VERSION ""

NS_ :

BS_:

BU_: CAN2 CAN1
VAL_TABLE_ VCU_DASH_GearRange_t 3 "Gear_Invalid" 2 "Gear_Reverse" 1 "Gear_Drive" 0 "Gear_Neutral" ;

BO_ 3221225472 VECTOR__INDEPENDENT_SIG_MSG: 0 Vector__XXX
 SG_ VCU_DVD_SOCLowerFailure : 0|1@0+ (1,0) [0|0] "" Vector__XXX
 SG_ VCU_DASH_VehicleController : 0|2@1+ (1,0) [0|0] "" Vector__XXX
 SG_ New_Signal_230 : 0|8@1+ (1,0) [0|0] "" Vector__XXX
 SG_ New_Signal_228 : 0|8@1+ (1,0) [0|0] "" Vector__XXX
 SG_ New_Signal_227 : 0|8@1+ (1,0) [0|0] "" Vector__XXX
 SG_ New_Signal_226 : 0|8@1+ (1,0) [0|0] "" Vector__XXX
 SG_ New_Signal_224 : 0|8@1+ (1,0) [0|0] "" Vector__XXX
 SG_ New_Signal_223 : 0|8@1+ (1,0) [0|0] "" Vector__XXX
 SG_ New_Signal_222 : 0|8@1+ (1,0) [0|0] "" Vector__XXX
 SG_ New_Signal_164 : 0|8@1+ (1,0) [0|0] "" Vector__XXX
 SG_ New_Signal_163 : 0|8@1+ (1,0) [0|0] "" Vector__XXX
 SG_ New_Signal_148 : 0|8@1+ (1,0) [0|0] "" Vector__XXX
 SG_ New_Signal_147 : 0|8@1+ (1,0) [0|0] "" Vector__XXX
 SG_ New_Signal_146 : 0|8@1+ (1,0) [0|0] "" Vector__XXX
 SG_ New_Signal_145 : 0|8@1+ (1,0) [0|0] "" Vector__XXX
 SG_ New_Signal_104 : 0|8@1+ (1,0) [0|0] "" Vector__XXX
 SG_ New_Signal_103 : 0|8@1+ (1,0) [0|0] "" Vector__XXX
 SG_ New_Signal_102 : 0|8@1+ (1,0) [0|0] "" Vector__XXX
 SG_ ERROR_CODE : 0|2@1- (1,0) [0|0] "" Vector__XXX
 SG_ DIN_P53 : 0|8@1+ (1,0) [0|255] "" Vector__XXX
 SG_ VCU_Vechicle_Speed : 0|8@1+ (1,0) [0|0] "km/h" Vector__XXX
 SG_ VCU_Motor_Rpm : 0|16@0+ (1,0) [0|30000] "rpm" Vector__XXX
 SG_ VCU_Driving_Range : 0|16@1+ (1,0) [0|0] "km" Vector__XXX
 SG_ New_Signal_211 : 0|8@1+ (1,0) [0|0] "" Vector__XXX
 SG_ New_Signal_213 : 0|8@1+ (1,0) [0|0] "" Vector__XXX
 SG_ New_Signal_212 : 0|8@1+ (1,0) [0|0] "" Vector__XXX
 SG_ New_Signal_211 : 0|8@1+ (1,0) [0|0] "" Vector__XXX
 SG_ New_Signal_210 : 0|8@1+ (1,0) [0|0] "" Vector__XXX
 SG_ New_Signal_196 : 0|8@1+ (1,0) [0|0] "" Vector__XXX
 SG_ New_Signal_195 : 0|8@1+ (1,0) [0|0] "" Vector__XXX
 SG_ New_Signal_194 : 0|8@1+ (1,0) [0|0] "" Vector__XXX
 SG_ New_Signal_193 : 0|8@1+ (1,0) [0|0] "" Vector__XXX
 SG_ New_Signal_192 : 0|8@1+ (1,0) [0|0] "" Vector__XXX
 SG_ New_Signal_191 : 0|8@1+ (1,0) [0|0] "" Vector__XXX
 SG_ New_Signal_170 : 0|8@1+ (1,0) [0|0] "" Vector__XXX
 SG_ New_Signal_169 : 0|8@1+ (1,0) [0|0] "" Vector__XXX
 SG_ New_Signal_168 : 0|8@1+ (1,0) [0|0] "" Vector__XXX
 SG_ New_Signal_167 : 0|8@1+ (1,0) [0|0] "" Vector__XXX
 SG_ New_Signal_166 : 0|8@1+ (1,0) [0|0] "" Vector__XXX
 SG_ New_Signal_165 : 0|8@1+ (1,0) [0|0] "" Vector__XXX

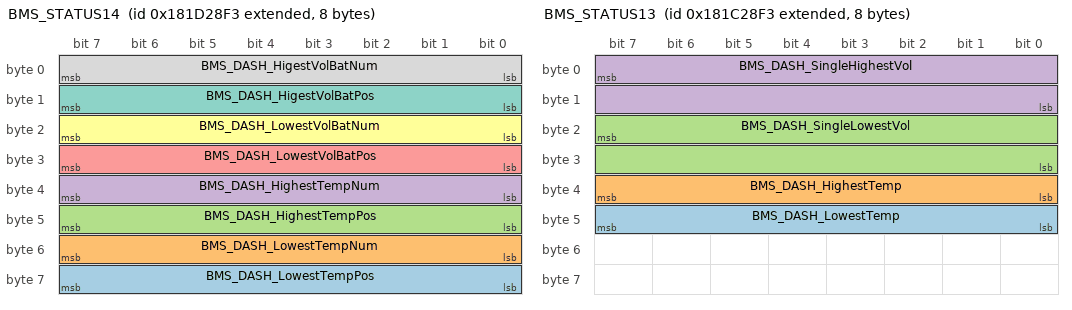
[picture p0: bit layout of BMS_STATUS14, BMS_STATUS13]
BO_ 2552047859 BMS_STATUS14: 8 CAN1
 SG_ BMS_DASH_LowestTempPos : 63|8@0+ (1,0) [0|0] "" Vector__XXX
 SG_ BMS_DASH_LowestTempNum : 55|8@0+ (1,0) [0|0] "" Vector__XXX
 SG_ BMS_DASH_HighestTempPos : 47|8@0+ (1,0) [0|0] "" Vector__XXX
 SG_ BMS_DASH_HighestTempNum : 39|8@0+ (1,0) [0|0] "" Vector__XXX
 SG_ BMS_DASH_LowestVolBatPos : 31|8@0+ (1,0) [0|0] "" Vector__XXX
 SG_ BMS_DASH_LowestVolBatNum : 23|8@0+ (1,0) [0|0] "" Vector__XXX
 SG_ BMS_DASH_HigestVolBatPos : 15|8@0+ (1,0) [0|0] "" Vector__XXX
 SG_ BMS_DASH_HigestVolBatNum : 7|8@0+ (1,0) [0|0] "" Vector__XXX

BO_ 2551982323 BMS_STATUS13: 8 CAN1
 SG_ BMS_DASH_LowestTemp : 47|8@0+ (1,-40) [-40|210] "" Vector__XXX
 SG_ BMS_DASH_HighestTemp : 39|8@0+ (1,-40) [-40|210] "" Vector__XXX
 SG_ BMS_DASH_SingleLowestVol : 23|16@0+ (0.01,0) [0|10] "V" Vector__XXX
 SG_ BMS_DASH_SingleHighestVol : 7|16@0+ (0.01,0) [0|10] "V" Vector__XXX

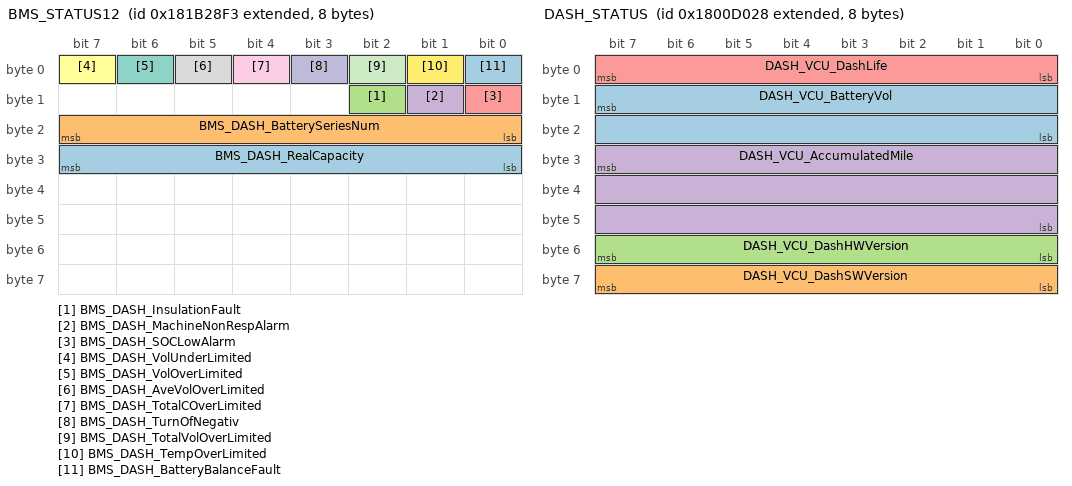
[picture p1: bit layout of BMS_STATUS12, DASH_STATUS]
BO_ 2551916787 BMS_STATUS12: 8 CAN1
 SG_ BMS_DASH_RealCapacity : 31|8@0+ (1,0) [0|510] "Ah" Vector__XXX
 SG_ BMS_DASH_BatterySeriesNum : 23|8@0+ (1,0) [0|0] "" Vector__XXX
 SG_ BMS_DASH_InsulationFault : 10|1@0+ (1,0) [0|0] "" Vector__XXX
 SG_ BMS_DASH_MachineNonRespAlarm : 9|1@0+ (1,0) [0|0] "" Vector__XXX
 SG_ BMS_DASH_SOCLowAlarm : 8|1@0+ (1,0) [0|0] "" Vector__XXX
 SG_ BMS_DASH_VolUnderLimited : 7|1@0+ (1,0) [0|0] "" Vector__XXX
 SG_ BMS_DASH_VolOverLimited : 6|1@0+ (1,0) [0|0] "" Vector__XXX
 SG_ BMS_DASH_AveVolOverLimited : 5|1@0+ (1,0) [0|0] "" Vector__XXX
 SG_ BMS_DASH_TotalCOverLimited : 4|1@0+ (1,0) [0|0] "" Vector__XXX
 SG_ BMS_DASH_TurnOfNegativ : 3|1@0+ (1,0) [0|0] "" Vector__XXX
 SG_ BMS_DASH_TotalVolOverLimited : 2|1@0+ (1,0) [0|0] "" Vector__XXX
 SG_ BMS_DASH_TempOverLimited : 1|1@0+ (1,0) [0|0] "" Vector__XXX
 SG_ BMS_DASH_BatteryBalanceFault : 0|1@0+ (1,0) [0|0] "" Vector__XXX

BO_ 2550474995 BatteryModule2: 8 Vector__XXX

BO_ 2551130355 Unknown55: 8 Vector__XXX

BO_ 2551064819 Unknown54: 8 Vector__XXX

BO_ 2550999283 BatteryModuleTemp10: 8 Vector__XXX

BO_ 2550409459 BatteryModuleTemp1: 8 Vector__XXX
 SG_ batteryModuletemp1 : 7|24@0+ (1,-40) [0|0] "" Vector__XXX

BO_ 2564958451 CellBatteryVol17_20: 8 CAN1

BO_ 2564892915 CellBatteryVol21_24: 8 CAN1

BO_ 2564827379 CellBatteryVol25_28: 8 CAN1

BO_ 2564761843 CellBatteryVol29_32: 8 CAN1

BO_ 2564696307 CellBatteryVol33_36: 8 CAN1

BO_ 2564630771 CellBatteryVol37_40: 8 CAN1

BO_ 2564565235 CellBatteryVol41_44: 8 CAN1

BO_ 2564499699 CellBatteryVol45_48: 8 CAN1

BO_ 2564434163 CellBatteryVol49_52: 8 CAN1

BO_ 2564368627 CellBatteryVol53_56: 8 CAN1

BO_ 2564303091 CellBatteryVol57_60: 8 CAN1

BO_ 2564237555 CellBatteryVol61_64: 8 CAN1

BO_ 2564172019 CellBatteryVol65_68: 8 CAN1

BO_ 2564106483 CellBatteryVol69_72: 8 CAN1

BO_ 2564040947 CellBatteryVol73_76: 8 CAN1

BO_ 2563975411 CellBatteryVol77_80: 8 CAN1

BO_ 2563909875 CellBatteryVol81_84: 8 CAN1

BO_ 2498684368 Unknown31: 8 Vector__XXX

BO_ 2550190120 DASH_STATUS: 8 CAN1
 SG_ DASH_VCU_BatteryVol : 15|16@0+ (0.1,0) [0|100] "V" Vector__XXX
 SG_ DASH_VCU_DashSWVersion : 63|8@0+ (1,0) [0|0] "" Vector__XXX
 SG_ DASH_VCU_DashHWVersion : 55|8@0+ (1,0) [0|0] "" Vector__XXX
 SG_ DASH_VCU_AccumulatedMile : 31|24@0+ (1,0) [0|16777215] "" Vector__XXX
 SG_ DASH_VCU_DashLife : 7|8@0+ (1,0) [0|0] "" Vector__XXX

BO_ 2550540496 DASH_CONTROL5: 8 CAN1
 SG_ VCU_DASH_VCUSWVersionNumber : 63|8@0+ (1,0) [0|0] "" Vector__XXX
 SG_ VCU_DASH_VCUHWVersionNumber : 55|8@0+ (1,0) [0|0] "" Vector__XXX

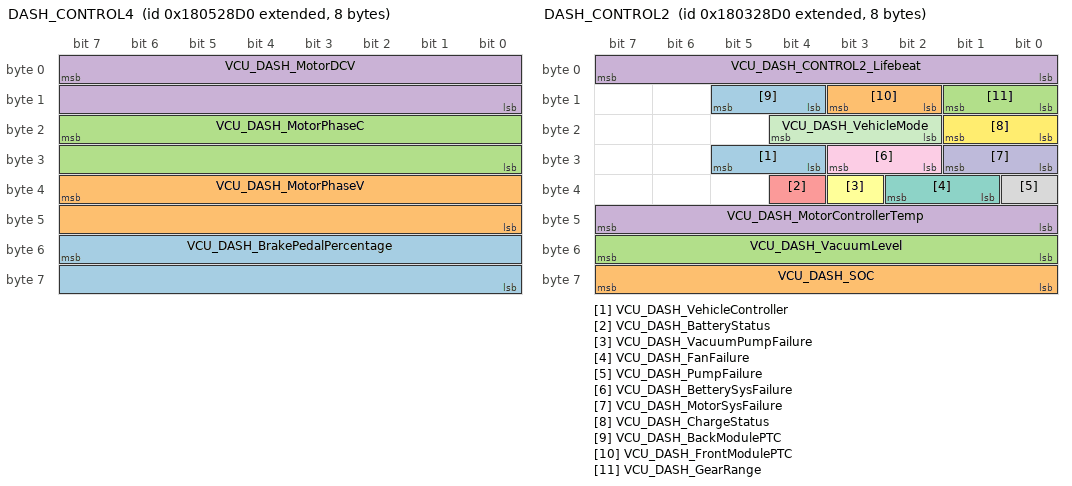
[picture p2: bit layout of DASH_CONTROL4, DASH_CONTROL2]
BO_ 2550474960 DASH_CONTROL4: 8 CAN1
 SG_ VCU_DASH_BrakePedalPercentage : 55|16@0+ (0.4,0) [0|250] "%" Vector__XXX
 SG_ VCU_DASH_MotorPhaseV : 39|16@0+ (1,0) [0|600] "V" Vector__XXX
 SG_ VCU_DASH_MotorPhaseC : 23|16@0+ (0.1,-500) [-500|500] "A" Vector__XXX
 SG_ VCU_DASH_MotorDCV : 7|16@0+ (0.1,0) [0|1000] "V" Vector__XXX

BO_ 2550409424 DASH_CONTROL3: 8 CAN1
 SG_ VCU_DASH_MotorHWLoseSignal_P : 62|1@0+ (1,0) [0|0] "" Vector__XXX
 SG_ VCU_DASH_MotorResolve_P : 61|1@0+ (1,0) [0|0] "" Vector__XXX
 SG_ VCU_DASH_MotorLackphase_P : 60|1@0+ (1,0) [0|0] "" Vector__XXX
 SG_ VCU_DASH_MotorCounterEMF_P : 59|1@0+ (1,0) [0|0] "" Vector__XXX
 SG_ VCU_DASH_MotorCANFailure_P : 58|1@0+ (1,0) [0|0] "" Vector__XXX
 SG_ VCU_DASH_MotorOverSpeed_P : 57|1@0+ (1,0) [0|0] "" Vector__XXX
 SG_ VCU_DASH_MotorDriverBoardOverT_P : 56|1@0+ (1,0) [0|0] "" Vector__XXX
 SG_ VCU_DASH_MotorBlocking_P : 55|1@0+ (1,0) [0|0] "" Vector__XXX
 SG_ VCU_DASH_MotorOverload_P : 54|1@0+ (1,0) [0|0] "" Vector__XXX
 SG_ VCU_DASH_MotorOverTorque_P : 53|1@0+ (1,0) [0|0] "" Vector__XXX
 SG_ VCU_DASH_MotorBusLineOverV_P : 52|1@0+ (1,0) [0|0] "" Vector__XXX
 SG_ VCU_DASH_MotorBusLineUnderV_P : 51|1@0+ (1,0) [0|0] "" Vector__XXX
 SG_ VCU_DASH_MotorDQOverC_P : 50|1@0+ (1,0) [0|0] "" Vector__XXX
 SG_ VCU_DASH_MotorCVOverV_P : 49|1@0+ (1,0) [0|0] "" Vector__XXX
 SG_ VCU_DASH_MotorCVReverseConn_P : 48|1@0+ (1,0) [0|0] "" Vector__XXX
 SG_ VCU_DASH_MotorCVUnderV_P : 47|1@0+ (1,0) [0|0] "" Vector__XXX
 SG_ VCU_DASH_MotorPhaseOverC_P : 46|1@0+ (1,0) [0|0] "" Vector__XXX
 SG_ VCU_DASH_MotorBusLineOverC_P : 45|1@0+ (1,0) [0|0] "" Vector__XXX
 SG_ VCU_DASH_MotorOverT_P : 44|1@0+ (1,0) [0|0] "" Vector__XXX
 SG_ VCU_DASH_MotorIGBTOverT_P : 43|1@0+ (1,0) [0|0] "" Vector__XXX
 SG_ VCU_DASH_MotorBridgeUpDown_P : 42|1@0+ (1,0) [0|0] "" Vector__XXX
 SG_ VCU_DASH_MotorDrivePowerUnderV_P : 41|1@0+ (1,0) [0|0] "" Vector__XXX
 SG_ VCU_DASH_MotorIGBT_P : 40|1@0+ (1,0) [0|0] "" Vector__XXX
 SG_ VCU_DASH_RPM : 31|16@0+ (1,-15000) [-15000|15000] "rpm" Vector__XXX
 SG_ VCU_DASH_DrivingMile : 15|16@0+ (1,0) [0|65535] "Km" Vector__XXX
 SG_ VCU_DASH_VehicleSpeed : 7|8@0+ (1,0) [0|255] "Km/h" Vector__XXX

BO_ 2550343888 DASH_CONTROL2: 8 CAN1
 SG_ VCU_DASH_VehicleController : 29|2@0+ (1,0) [0|0] "" Vector__XXX
 SG_ VCU_DASH_SOC : 63|8@0+ (0.4,0) [0|100] "%" Vector__XXX
 SG_ VCU_DASH_VacuumLevel : 55|8@0+ (0.01,0) [0|2] "Bar" Vector__XXX
 SG_ VCU_DASH_MotorControllerTemp : 47|8@0+ (1,-40) [-40|210] "°C" Vector__XXX
 SG_ VCU_DASH_BatteryStatus : 36|1@0+ (1,0) [0|0] "" Vector__XXX
 SG_ VCU_DASH_VacuumPumpFailure : 35|1@0+ (1,0) [0|0] "" Vector__XXX
 SG_ VCU_DASH_FanFailure : 34|2@0+ (1,0) [0|0] "" Vector__XXX
 SG_ VCU_DASH_PumpFailure : 32|1@0+ (1,0) [0|0] "" Vector__XXX
 SG_ VCU_DASH_BetterySysFailure : 27|2@0+ (1,0) [0|0] "" Vector__XXX
 SG_ VCU_DASH_MotorSysFailure : 25|2@0+ (1,0) [0|0] "" Vector__XXX
 SG_ VCU_DASH_VehicleMode : 20|3@0+ (1,0) [0|0] "" Vector__XXX
 SG_ VCU_DASH_ChargeStatus : 17|2@0+ (1,0) [0|0] "" Vector__XXX
 SG_ VCU_DASH_BackModulePTC : 13|2@0+ (1,0) [0|0] "" Vector__XXX
 SG_ VCU_DASH_FrontModulePTC : 11|2@0+ (1,0) [0|0] "" Vector__XXX
 SG_ VCU_DASH_GearRange : 9|2@0+ (1,0) [0|0] "" Vector__XXX
 SG_ VCU_DASH_CONTROL2_Lifebeat : 7|8@0+ (1,0) [0|0] "" Vector__XXX

BO_ 2550278352 DASH_CONTROL1: 8 CAN1
 SG_ VCU_DASH_PowerOrEcoMode : 63|1@0+ (1,0) [0|0] "" Vector__XXX
 SG_ VCU_DASH_FootBrake : 62|1@0+ (1,0) [0|0] "" Vector__XXX
 SG_ VCU_DASH_Handbrake : 61|1@0+ (1,0) [0|0] "" Vector__XXX
 SG_ VCU_DASH_AirConditioning : 60|1@0+ (1,0) [0|0] "" Vector__XXX
 SG_ VCU_DASH_VacuumPump : 59|1@0+ (1,0) [0|0] "" Vector__XXX
 SG_ VCU_DASH_HighSpeedFan : 58|1@0+ (1,0) [0|0] "" Vector__XXX
 SG_ VCU_DASH_LowSpeedFan : 57|1@0+ (1,0) [0|0] "" Vector__XXX
 SG_ VCU_DASH_Pumps : 56|1@0+ (1,0) [0|0] "" Vector__XXX
 SG_ VCU_DASH_MotorTemp : 55|8@0+ (1,-40) [-40|210] "°C" Vector__XXX
 SG_ VCU_DASH_TorqueControl : 39|16@0+ (0.1,-30000) [-3000|3000] "N.m" Vector__XXX
 SG_ VCU_DASH_AccelPedalPercentage : 23|16@0+ (0.4,0) [0|100] "%" Vector__XXX
 SG_ VCU_DASH_DCStatus : 15|1@0+ (1,0) [0|0] "" Vector__XXX
 SG_ VCU_DASH_BatteryUndervoltage : 14|1@0+ (1,0) [0|0] "" Vector__XXX
 SG_ VCU_DASH_VacuumFailure : 13|1@0+ (1,0) [0|0] "" Vector__XXX
 SG_ VCU_DASH_ControllerFailure : 12|2@0+ (1,0) [0|0] "" Vector__XXX
 SG_ VCU_DASH_CONTROL1_Lifebeat : 7|8@0+ (1,0) [0|0] "" Vector__XXX
 SG_ VCU_DASH_VehicleOperatingState : 10|3@0+ (1,0) [0|0] "" Vector__XXX

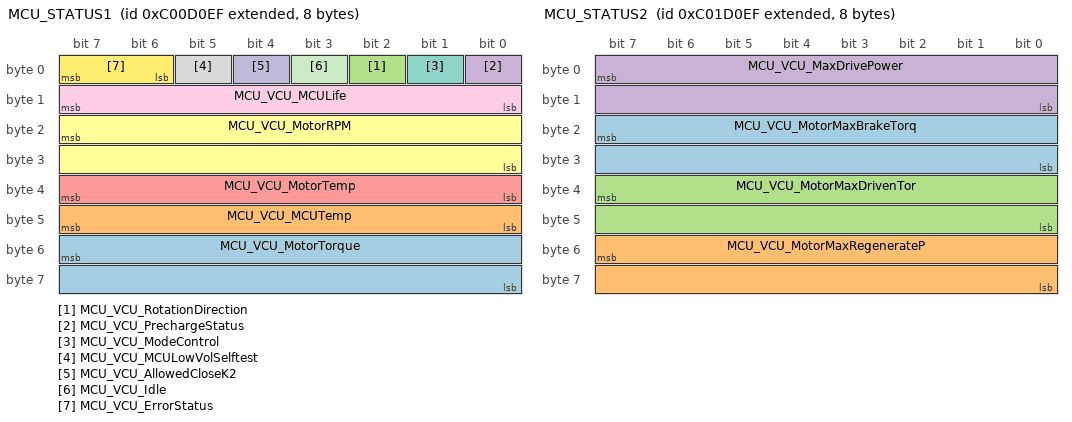
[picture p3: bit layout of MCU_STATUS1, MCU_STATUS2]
BO_ 2348863727 MCU_STATUS1: 8 CAN2
 SG_ MCU_VCU_MotorTorque : 55|16@0+ (0.1,-30000) [-3000|3000] "Nm" Vector__XXX
 SG_ MCU_VCU_MCUTemp : 47|8@0+ (1,-40) [-40|210] "C" Vector__XXX
 SG_ MCU_VCU_RotationDirection : 2|1@0+ (1,0) [0|0] "" Vector__XXX
 SG_ MCU_VCU_PrechargeStatus : 0|1@0+ (1,0) [0|0] "" Vector__XXX
 SG_ MCU_VCU_MotorTemp : 39|8@0+ (1,-40) [-40|210] "C" Vector__XXX
 SG_ MCU_VCU_MotorRPM : 23|16@0+ (1,-15000) [-15000|15000] "" Vector__XXX
 SG_ MCU_VCU_ModeControl : 1|1@0+ (1,0) [0|0] "" Vector__XXX
 SG_ MCU_VCU_MCULowVolSelftest : 5|1@0+ (1,0) [0|0] "" Vector__XXX
 SG_ MCU_VCU_MCULife : 15|8@0+ (1,0) [0|0] "" Vector__XXX
 SG_ MCU_VCU_AllowedCloseK2 : 4|1@0+ (1,0) [0|0] "" Vector__XXX
 SG_ MCU_VCU_Idle : 3|1@0+ (1,0) [0|0] "" Vector__XXX
 SG_ MCU_VCU_ErrorStatus : 7|2@0+ (1,0) [0|0] "" Vector__XXX

BO_ 2348929263 MCU_STATUS2: 8 CAN2
 SG_ MCU_VCU_MotorMaxBrakeTorq : 23|16@0+ (0.1,-30000) [-3000|3000] "Nm" Vector__XXX
 SG_ MCU_VCU_MotorMaxRegenerateP : 55|16@0+ (0.01,-32000) [-320|320] "kw" Vector__XXX
 SG_ MCU_VCU_MotorMaxDrivenTor : 39|16@0+ (0.1,-30000) [-3000|3000] "Nm" Vector__XXX
 SG_ MCU_VCU_MaxDrivePower : 7|16@0+ (0.01,-32000) [-320|320] "kw" Vector__XXX

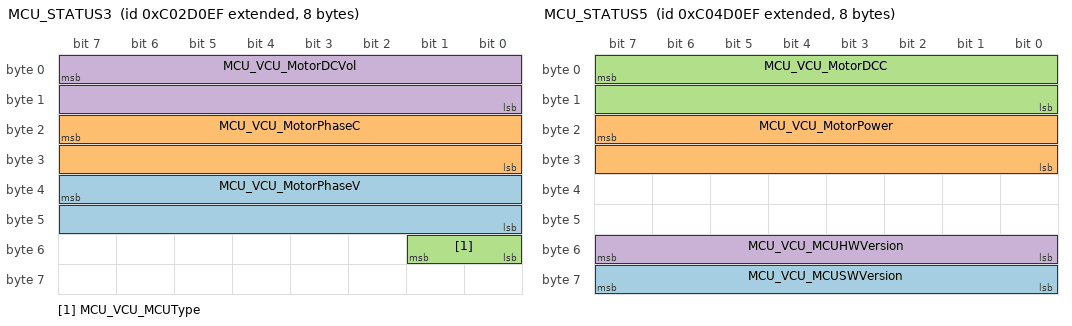
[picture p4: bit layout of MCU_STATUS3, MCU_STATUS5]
BO_ 2348994799 MCU_STATUS3: 8 CAN2
 SG_ MCU_VCU_MotorPhaseV : 39|16@0+ (1,0) [0|600] "V" Vector__XXX
 SG_ MCU_VCU_MotorPhaseC : 23|16@0+ (0.1,-5000) [-500|1000] "A" Vector__XXX
 SG_ MCU_VCU_MCUType : 49|2@0+ (1,0) [0|0] "" Vector__XXX
 SG_ MCU_VCU_MotorDCVol : 7|16@0+ (0.1,0) [0|1000] "V" Vector__XXX

BO_ 2349060335 MCU_STATUS4: 8 CAN2
 SG_ MCU_VCU_DischargeFailure : 23|1@0+ (1,0) [0|0] "" Vector__XXX
 SG_ MCU_VCU_MotorHWLoseSignal_P : 22|1@0+ (1,0) [0|0] "" Vector__XXX
 SG_ MCU_VCU_MotorResolve_P : 21|1@0+ (1,0) [0|0] "" Vector__XXX
 SG_ MCU_VCU_MotorLackphase_P : 20|1@0+ (1,0) [0|0] "" Vector__XXX
 SG_ MCU_VCU_VehicleFaultCircuitRes : 19|1@0+ (1,0) [0|0] "" Vector__XXX
 SG_ MCU_VCU_MotorCANComuiFailure_P : 18|1@0+ (1,0) [0|0] "" Vector__XXX
 SG_ MCU_VCU_MotorOverSpeed_P : 17|1@0+ (1,0) [0|0] "" Vector__XXX
 SG_ MCU_VCU_MotorDriverBoardOverT_P : 16|1@0+ (1,0) [0|0] "" Vector__XXX
 SG_ MCU_VCU_MotorBlocking_P : 15|1@0+ (1,0) [0|0] "" Vector__XXX
 SG_ MCU_VCU_MotorOverload_P : 14|1@0+ (1,0) [0|0] "" Vector__XXX
 SG_ MCU_VCU_MotorOverTorque_P : 13|1@0+ (1,0) [0|0] "" Vector__XXX
 SG_ MCU_VCU_MotorBusLineOverV_P : 12|1@0+ (1,0) [0|0] "" Vector__XXX
 SG_ MCU_VCU_MotorBusLineUnderV_P : 11|1@0+ (1,0) [0|0] "" Vector__XXX
 SG_ MCU_VCU_MotorDQOverC_P : 10|1@0+ (1,0) [0|0] "" Vector__XXX
 SG_ MCU_VCU_MotorCVOverV_P : 9|1@0+ (1,0) [0|0] "" Vector__XXX
 SG_ MCU_VCU_MotorCVReverseConn_P : 8|1@0+ (1,0) [0|0] "" Vector__XXX
 SG_ MCU_VCU_MotorCVUnderV_P : 7|1@0+ (1,0) [0|0] "" Vector__XXX
 SG_ MCU_VCU_MotorPhaseOverC_P : 6|1@0+ (1,0) [0|0] "" Vector__XXX
 SG_ MCU_VCU_MotorBusLineOverC_P : 5|1@0+ (1,0) [0|0] "" Vector__XXX
 SG_ MCU_VCU_MotorOverT_P : 4|1@0+ (1,0) [0|0] "" Vector__XXX
 SG_ MCU_VCU_MotorIGBTOverT_P : 3|1@0+ (1,0) [0|0] "" Vector__XXX
 SG_ MCU_VCU_MotorBridgeUpDown_P : 2|1@0+ (1,0) [0|0] "" Vector__XXX
 SG_ MCU_VCU_MotorDrivePowerUnderV_P : 1|1@0+ (1,0) [0|0] "" Vector__XXX
 SG_ MCU_VCU_MotorIGBT_P : 0|1@0+ (1,0) [0|0] "" Vector__XXX

BO_ 2349125871 MCU_STATUS5: 8 CAN2
 SG_ MCU_VCU_MCUSWVersion : 63|8@0+ (1,0) [0|0] " " Vector__XXX
 SG_ MCU_VCU_MotorPower : 23|16@0+ (0.01,0) [0|640] "kw" Vector__XXX
 SG_ MCU_VCU_MotorDCC : 7|16@0+ (0.1,0) [0|1000] "A" Vector__XXX
 SG_ MCU_VCU_MCUHWVersion : 55|8@0+ (1,0) [0|0] " " Vector__XXX

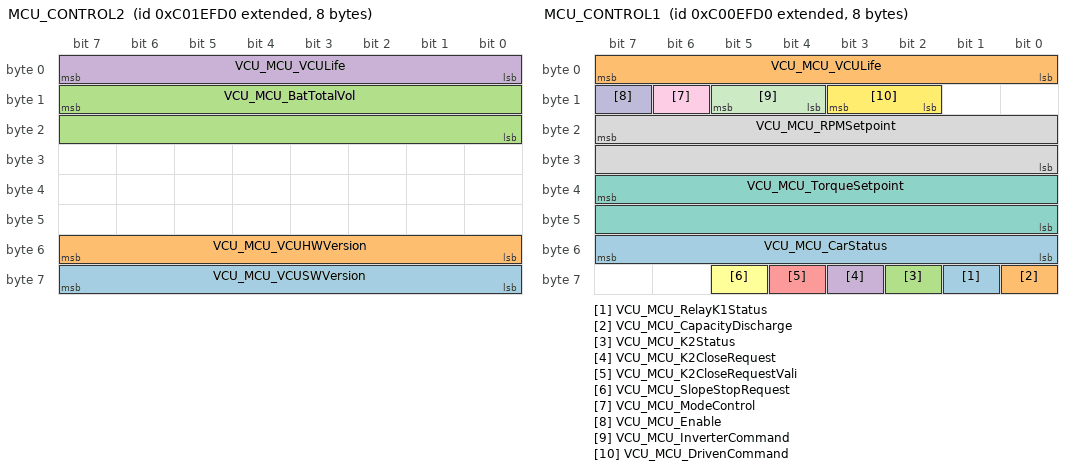
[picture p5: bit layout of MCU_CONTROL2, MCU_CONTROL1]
BO_ 2348937168 MCU_CONTROL2: 8 CAN2
 SG_ VCU_MCU_VCUSWVersion : 63|8@0+ (1,0) [0|0] " " Vector__XXX
 SG_ VCU_MCU_VCUHWVersion : 55|8@0+ (1,0) [0|0] " " Vector__XXX
 SG_ VCU_MCU_BatTotalVol : 15|16@0+ (0.1,0) [0|1000] "V" Vector__XXX
 SG_ VCU_MCU_VCULife : 7|8@0+ (1,0) [0|0] "" Vector__XXX

BO_ 2348871632 MCU_CONTROL1: 8 CAN2
 SG_ VCU_MCU_RelayK1Status : 57|1@0+ (1,0) [0|0] "" Vector__XXX
 SG_ VCU_MCU_CapacityDischarge : 56|1@0+ (1,0) [0|0] "" Vector__XXX
 SG_ VCU_MCU_K2Status : 58|1@0+ (1,0) [0|0] "" Vector__XXX
 SG_ VCU_MCU_K2CloseRequest : 59|1@0+ (1,0) [0|0] "" Vector__XXX
 SG_ VCU_MCU_K2CloseRequestVali : 60|1@0+ (1,0) [0|0] "" Vector__XXX
 SG_ VCU_MCU_SlopeStopRequest : 61|1@0+ (1,0) [0|0] "" Vector__XXX
 SG_ VCU_MCU_TorqueSetpoint : 39|16@0+ (0.1,-30000) [-3000|3000] "Nm" Vector__XXX
 SG_ VCU_MCU_RPMSetpoint : 23|16@0+ (1,-15000) [-15000|15000] "rpm" Vector__XXX
 SG_ VCU_MCU_ModeControl : 14|1@0+ (1,0) [0|0] "" Vector__XXX
 SG_ VCU_MCU_Enable : 15|1@0+ (1,0) [0|0] "" Vector__XXX
 SG_ VCU_MCU_InverterCommand : 13|2@0+ (1,0) [0|0] "" Vector__XXX
 SG_ VCU_MCU_DrivenCommand : 11|2@0+ (1,0) [0|0] "" Vector__XXX
 SG_ VCU_MCU_CarStatus : 55|8@0+ (1,0) [0|0] "" Vector__XXX
 SG_ VCU_MCU_VCULife : 7|8@0+ (1,0) [0|0] "" Vector__XXX

BO_ 2550933747 BatteryModuleTemp9: 8 CAN1

BO_ 2565023987 CellBatteryVol13_14: 8 CAN1

BO_ 2565089523 CellBatteryVol9_12: 8 CAN1

BO_ 2550868211 BatteryModuleTemp8: 8 CAN1

BO_ 2565155059 CellBatteryVol5_8: 8 CAN1

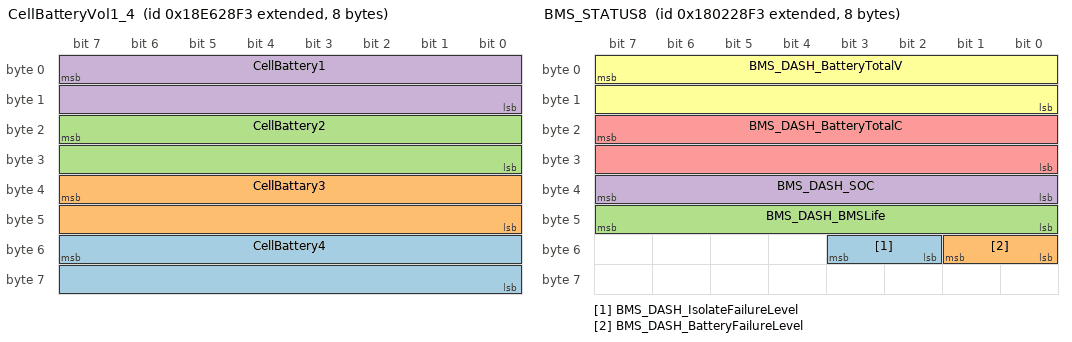
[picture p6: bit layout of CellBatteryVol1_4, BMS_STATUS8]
BO_ 2565220595 CellBatteryVol1_4: 8 CAN1
 SG_ CellBattery4 : 55|16@0+ (1,0) [0|511] "" Vector__XXX
 SG_ CellBattary3 : 39|16@0+ (1,0) [0|511] "" Vector__XXX
 SG_ CellBattery2 : 23|16@0+ (1,0) [0|511] "" Vector__XXX
 SG_ CellBattery1 : 7|16@0+ (1,0) [0|0] "" Vector__XXX

BO_ 2550802675 BatteryModuleTemp7: 8 CAN1

BO_ 2563254515 Unknown23: 8 Vector__XXX

BO_ 2563320051 CellBatteryVol117_120: 8 CAN1

BO_ 2550737139 BatteryModuleTemp6: 8 Vector__XXX

BO_ 2563385587 CellBatteryVol113_116: 8 CAN1

BO_ 2563451123 CellBatteryVol109_112: 8 CAN1

BO_ 2550671603 BatteryModuleTemp5: 8 Vector__XXX

BO_ 2563516659 CellBatteryVol105_108: 8 CAN1

BO_ 2563582195 CellBatteryVol101_104: 8 CAN1

BO_ 2550278387 BMS_STATUS8: 8 CAN1
 SG_ BMS_DASH_IsolateFailureLevel : 51|2@0+ (1,0) [0|0] "" Vector__XXX
 SG_ BMS_DASH_BatteryFailureLevel : 49|2@0+ (1,0) [0|0] "" Vector__XXX
 SG_ BMS_DASH_BMSLife : 47|8@0+ (1,0) [0|0] "" Vector__XXX
 SG_ BMS_DASH_SOC : 39|8@0+ (0.4,0) [0|250] "%" Vector__XXX
 SG_ BMS_DASH_BatteryTotalC : 23|16@0+ (0.1,-500) [-500|500] "A" Vector__XXX
 SG_ BMS_DASH_BatteryTotalV : 7|16@0+ (0.1,0) [0|6553.5] "V" Vector__XXX

BO_ 2550606067 BatteryModuleTemp4: 8 Vector__XXX

BO_ 2563647731 CellBatteryVol97_100: 8 CAN1

BO_ 2550180048 POWER_STEERING_CONTROL: 8 CAN1
 SG_ POWER_STEERING_Speed : 16|8@1+ (1,0) [0|0] "" Vector__XXX
 SG_ POWER_STEERING_Enable : 8|1@1+ (1,0) [0|0] "" Vector__XXX
 SG_ POWER_STEERING_ControlLifebeat : 0|8@1+ (1,0) [0|0] "" Vector__XXX

BO_ 2553719504 Unknown12: 8 Vector__XXX

BO_ 2553653968 Unknown11: 8 Vector__XXX

BO_ 2553391824 Unknown10: 8 Vector__XXX

BO_ 2553326288 Unknown9: 8 Vector__XXX

BO_ 2550377168 Unknown8: 8 Vector__XXX

BO_ 2550311632 Unknown7: 8 Vector__XXX

BO_ 2550246096 Unknown6: 8 Vector__XXX

BO_ 2563713267 CellBatteryVol93_96: 8 CAN1

BO_ 2550183120 DVD_CONTROL1: 8 CAN1
 SG_ VCU_DVD_SOCAlarmFailure : 48|1@0+ (1,0) [0|0] "" Vector__XXX
 SG_ VCU_DVD_DCDCDropped : 47|1@0+ (1,0) [0|0] "" Vector__XXX
 SG_ VCU_DVD_ACControllerDropped : 46|1@0+ (1,0) [0|0] "" Vector__XXX
 SG_ VCU_DVD_PowerSteeringDropped : 45|1@0+ (1,0) [0|0] "" Vector__XXX
 SG_ VCU_DVD_ChargerDropped : 44|1@0+ (1,0) [0|0] "" Vector__XXX
 SG_ VCU_DVD_SevereLowBatteryV : 43|1@0+ (1,0) [0|0] "" Vector__XXX
 SG_ VCU_DVD_PumpFailure : 42|1@0+ (1,0) [0|0] "" Vector__XXX
 SG_ VCU_DVD_SOC2Low : 39|1@0+ (1,0) [0|0] "" Vector__XXX
 SG_ VCU_DVD_SOCLow : 38|1@0+ (1,0) [0|0] "" Vector__XXX
 SG_ VCU_DVD_BatterySysDropped : 37|1@0+ (1,0) [0|0] "" Vector__XXX
 SG_ VCU_DVD_MotorDropped : 36|1@0+ (1,0) [0|0] "" Vector__XXX
 SG_ VCU_DVD_BatteryV2Low : 35|1@0+ (1,0) [0|0] "" Vector__XXX
 SG_ VCU_DVD_VaccumAlarm : 34|1@0+ (1,0) [0|0] "" Vector__XXX
 SG_ VCU_DVD_MotorControllerOverT : 33|1@0+ (1,0) [0|0] "" Vector__XXX
 SG_ VCU_DVD_PowerBatteryV2Low : 32|1@0+ (1,0) [0|0] "" Vector__XXX
 SG_ VCU_DVD_BrakeOC : 31|1@0+ (1,0) [0|0] "" Vector__XXX
 SG_ VCU_DVD_BrakeShort2Ground : 30|1@0+ (1,0) [0|0] "" Vector__XXX
 SG_ VCU_DVD_BrakeShort2Power : 29|1@0+ (1,0) [0|0] "" Vector__XXX
 SG_ VCU_DVD_BrakePerfAlarm : 28|1@0+ (1,0) [0|0] "" Vector__XXX
 SG_ VCU_DVD_AccelOC : 27|1@0+ (1,0) [0|0] "" Vector__XXX
 SG_ VCU_DVD_AccelShort2Ground : 26|1@0+ (1,0) [0|0] "" Vector__XXX
 SG_ VCU_DVD_AccelShort2Power : 25|1@0+ (1,0) [0|0] "" Vector__XXX
 SG_ VCU_DVD_AccelPerfAlarm : 24|1@0+ (1,0) [0|0] "" Vector__XXX
 SG_ VCU_DVD_ACAlarmLevel : 23|2@0+ (1,0) [0|0] "" Vector__XXX
 SG_ VCU_DVD_SteeringPumpAlarmL : 21|2@0+ (1,0) [0|0] "" Vector__XXX
 SG_ VCU_DVD_ChargerAlarmLevel : 19|2@0+ (1,0) [0|0] "" Vector__XXX
 SG_ VCU_DVD_DCDCAlarmLevel : 17|2@0+ (1,0) [0|0] "" Vector__XXX
 SG_ VCU_DVD_CarControllerAlarmLevel : 15|2@0+ (1,0) [0|0] "" Vector__XXX
 SG_ VCU_DVD_BatterySysAlarmLevel : 13|2@0+ (1,0) [0|0] "" Vector__XXX
 SG_ VCU_DVD_MotorAlarmLevel : 11|2@0+ (1,0) [0|0] "" Vector__XXX
 SG_ VCU_DVD_VehicleFaultLevel : 9|2@0+ (1,0) [0|0] "" Vector__XXX

BO_ 2550248656 DVD_CONTROL2_MOTOR: 8 CAN1
 SG_ VCU_DVD_DischargeFailure : 23|1@0+ (1,0) [0|0] "" Vector__XXX
 SG_ VCU_DVD_MotorHWLoseSignal_P : 22|1@0+ (1,0) [0|0] "" Vector__XXX
 SG_ VCU_DVD_MotorResolve_P : 21|1@0+ (1,0) [0|0] "" Vector__XXX
 SG_ VCU_DVD_MotorLackphase_P : 20|1@0+ (1,0) [0|0] "" Vector__XXX
 SG_ VCU_DVD_VehicleFaultCircuitRes : 19|1@0+ (1,0) [0|0] "" Vector__XXX
 SG_ VCU_DVD_MotorCANComuiFailure_P : 18|1@0+ (1,0) [0|0] "" Vector__XXX
 SG_ VCU_DVD_MotorOverSpeed_P : 17|1@0+ (1,0) [0|0] "" Vector__XXX
 SG_ VCU_DVD_MotorDriverBoardOverT_P : 16|1@0+ (1,0) [0|0] "" Vector__XXX
 SG_ VCU_DVD_MotorBlocking_P : 15|1@0+ (1,0) [0|0] "" Vector__XXX
 SG_ VCU_DVD_MotorOverload_P : 14|1@0+ (1,0) [0|0] "" Vector__XXX
 SG_ VCU_DVD_MotorOverTorque_P : 13|1@0+ (1,0) [0|0] "" Vector__XXX
 SG_ VCU_DVD_MotorBusLineOverV_P : 12|1@0+ (1,0) [0|0] "" Vector__XXX
 SG_ VCU_DVD_MotorBusLineUnderV_P : 11|1@0+ (1,0) [0|0] "" Vector__XXX
 SG_ VCU_DVD_MotorDQOverC_P : 10|1@0+ (1,0) [0|0] "" Vector__XXX
 SG_ VCU_DVD_MotorCVOverV_P : 9|1@0+ (1,0) [0|0] "" Vector__XXX
 SG_ VCU_DVD_MotorCVReverseConn_P : 8|1@0+ (1,0) [0|0] "" Vector__XXX
 SG_ VCU_DVD_MotorCVUnderV_P : 7|1@0+ (1,0) [0|0] "" Vector__XXX
 SG_ VCU_DVD_MotorPhaseOverC_P : 6|1@0+ (1,0) [0|0] "" Vector__XXX
 SG_ VCU_DVD_MotorBusLineOverC_P : 5|1@0+ (1,0) [0|0] "" Vector__XXX
 SG_ VCU_DVD_MotorOverT_P : 4|1@0+ (1,0) [0|0] "" Vector__XXX
 SG_ VCU_DVD_MotorIGBTOverT_P : 3|1@0+ (1,0) [0|0] "" Vector__XXX
 SG_ VCU_DVD_MotorBridgeUpDown_P : 2|1@0+ (1,0) [0|0] "" Vector__XXX
 SG_ VCU_DVD_MotorDrivePowerUnderV_P : 1|1@0+ (1,0) [0|0] "" Vector__XXX
 SG_ VCU_DVD_MotorIGBT_P : 0|1@0+ (1,0) [0|0] "" Vector__XXX

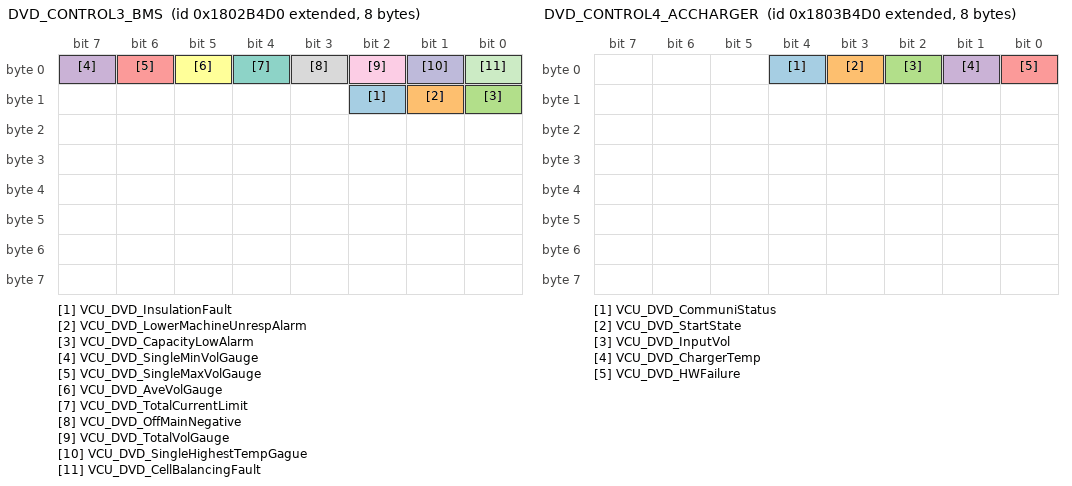
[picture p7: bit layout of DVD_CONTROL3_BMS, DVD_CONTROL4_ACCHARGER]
BO_ 2550314192 DVD_CONTROL3_BMS: 8 CAN1
 SG_ VCU_DVD_InsulationFault : 10|1@0+ (1,0) [0|0] "" Vector__XXX
 SG_ VCU_DVD_LowerMachineUnrespAlarm : 9|1@0+ (1,0) [0|0] "" Vector__XXX
 SG_ VCU_DVD_CapacityLowAlarm : 8|1@0+ (1,0) [0|0] "" Vector__XXX
 SG_ VCU_DVD_SingleMinVolGauge : 7|1@0+ (1,0) [0|0] "" Vector__XXX
 SG_ VCU_DVD_SingleMaxVolGauge : 6|1@0+ (1,0) [0|0] "" Vector__XXX
 SG_ VCU_DVD_AveVolGauge : 5|1@0+ (1,0) [0|0] "" Vector__XXX
 SG_ VCU_DVD_TotalCurrentLimit : 4|1@0+ (1,0) [0|0] "" Vector__XXX
 SG_ VCU_DVD_OffMainNegative : 3|1@0+ (1,0) [0|0] "" Vector__XXX
 SG_ VCU_DVD_TotalVolGauge : 2|1@0+ (1,0) [0|0] "" Vector__XXX
 SG_ VCU_DVD_SingleHighestTempGague : 1|1@0+ (1,0) [0|0] "" Vector__XXX
 SG_ VCU_DVD_CellBalancingFault : 0|1@0+ (1,0) [0|0] "" Vector__XXX

BO_ 2550379728 DVD_CONTROL4_ACCHARGER: 8 CAN1
 SG_ VCU_DVD_CommuniStatus : 4|1@0+ (1,0) [0|0] "" Vector__XXX
 SG_ VCU_DVD_StartState : 3|1@0+ (1,0) [0|0] "" Vector__XXX
 SG_ VCU_DVD_InputVol : 2|1@0+ (1,0) [0|0] "" Vector__XXX
 SG_ VCU_DVD_ChargerTemp : 1|1@0+ (1,0) [0|0] "" Vector__XXX
 SG_ VCU_DVD_HWFailure : 0|1@0+ (1,0) [0|0] "" Vector__XXX

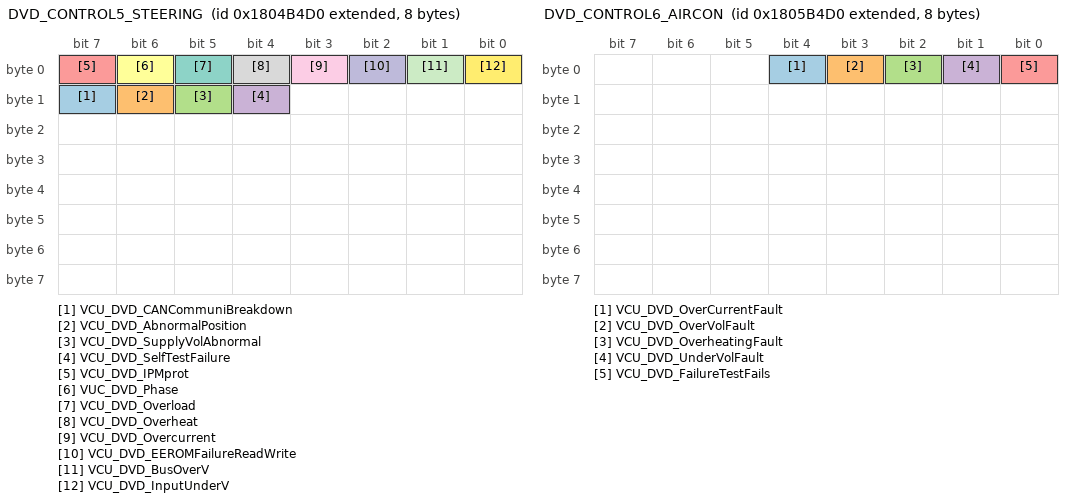
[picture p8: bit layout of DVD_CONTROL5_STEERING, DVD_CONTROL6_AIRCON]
BO_ 2550445264 DVD_CONTROL5_STEERING: 8 CAN1
 SG_ VCU_DVD_CANCommuniBreakdown : 15|1@0+ (1,0) [0|0] "" Vector__XXX
 SG_ VCU_DVD_AbnormalPosition : 14|1@0+ (1,0) [0|0] "" Vector__XXX
 SG_ VCU_DVD_SupplyVolAbnormal : 13|1@0+ (1,0) [0|0] "" Vector__XXX
 SG_ VCU_DVD_SelfTestFailure : 12|1@0+ (1,0) [0|0] "" Vector__XXX
 SG_ VCU_DVD_IPMprot : 7|1@0+ (1,0) [0|0] "" Vector__XXX
 SG_ VUC_DVD_Phase : 6|1@0+ (1,0) [0|0] "" Vector__XXX
 SG_ VCU_DVD_Overload : 5|1@0+ (1,0) [0|0] "" Vector__XXX
 SG_ VCU_DVD_Overheat : 4|1@0+ (1,0) [0|0] "" Vector__XXX
 SG_ VCU_DVD_Overcurrent : 3|1@0+ (1,0) [0|0] "" Vector__XXX
 SG_ VCU_DVD_EEROMFailureReadWrite : 2|1@0+ (1,0) [0|0] "" Vector__XXX
 SG_ VCU_DVD_BusOverV : 1|1@0+ (1,0) [0|0] "" Vector__XXX
 SG_ VCU_DVD_InputUnderV : 0|1@0+ (1,0) [0|0] "" Vector__XXX

BO_ 2550510800 DVD_CONTROL6_AIRCON: 8 CAN1
 SG_ VCU_DVD_OverCurrentFault : 4|1@0+ (1,0) [0|0] "" Vector__XXX
 SG_ VCU_DVD_OverVolFault : 3|1@0+ (1,0) [0|0] "" Vector__XXX
 SG_ VCU_DVD_OverheatingFault : 2|1@0+ (1,0) [0|0] "" Vector__XXX
 SG_ VCU_DVD_UnderVolFault : 1|1@0+ (1,0) [0|0] "" Vector__XXX
 SG_ VCU_DVD_FailureTestFails : 0|1@0+ (1,0) [0|0] "" Vector__XXX

BO_ 2550180560 Unknown4: 8 Vector__XXX

BO_ 2550540531 BatteryModuleTemp3: 8 Vector__XXX

BO_ 2563778803 CellBatteryVol89_92: 8 CAN1

BO_ 2563844339 CellBatteryVol85_88: 8 CAN1

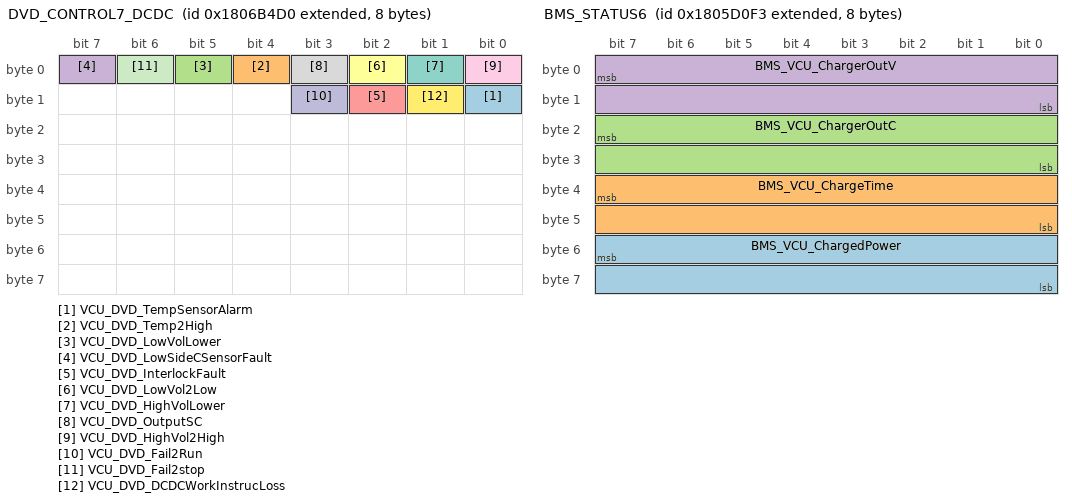
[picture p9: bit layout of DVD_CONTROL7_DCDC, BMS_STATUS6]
BO_ 2550576336 DVD_CONTROL7_DCDC: 8 CAN1
 SG_ VCU_DVD_TempSensorAlarm : 8|1@0+ (1,0) [0|0] "" Vector__XXX
 SG_ VCU_DVD_Temp2High : 4|1@0+ (1,0) [0|0] "" Vector__XXX
 SG_ VCU_DVD_LowVolLower : 5|1@0+ (1,0) [0|0] "" Vector__XXX
 SG_ VCU_DVD_LowSideCSensorFault : 7|1@0+ (1,0) [0|0] "" Vector__XXX
 SG_ VCU_DVD_InterlockFault : 10|1@0+ (1,0) [0|0] "" Vector__XXX
 SG_ VCU_DVD_LowVol2Low : 2|1@0+ (1,0) [0|0] "" Vector__XXX
 SG_ VCU_DVD_HighVolLower : 1|1@0+ (1,0) [0|0] "" Vector__XXX
 SG_ VCU_DVD_OutputSC : 3|1@0+ (1,0) [0|0] "" Vector__XXX
 SG_ VCU_DVD_HighVol2High : 0|1@0+ (1,0) [0|0] "" Vector__XXX
 SG_ VCU_DVD_Fail2Run : 11|1@0+ (1,0) [0|0] "" Vector__XXX
 SG_ VCU_DVD_Fail2stop : 6|1@0+ (1,0) [0|0] "" Vector__XXX
 SG_ VCU_DVD_DCDCWorkInstrucLoss : 9|1@0+ (1,0) [0|0] "" Vector__XXX

BO_ 2550518003 BMS_STATUS6: 8 CAN1
 SG_ BMS_VCU_ChargedPower : 55|16@0+ (1,0) [0|1000] "kwh" Vector__XXX
 SG_ BMS_VCU_ChargeTime : 39|16@0+ (1,0) [0|600] "min" Vector__XXX
 SG_ BMS_VCU_ChargerOutC : 23|16@0+ (0.1,-5000) [-500|500] "A" Vector__XXX
 SG_ BMS_VCU_ChargerOutV : 7|16@0+ (0.1,0) [0|1000] "V" Vector__XXX

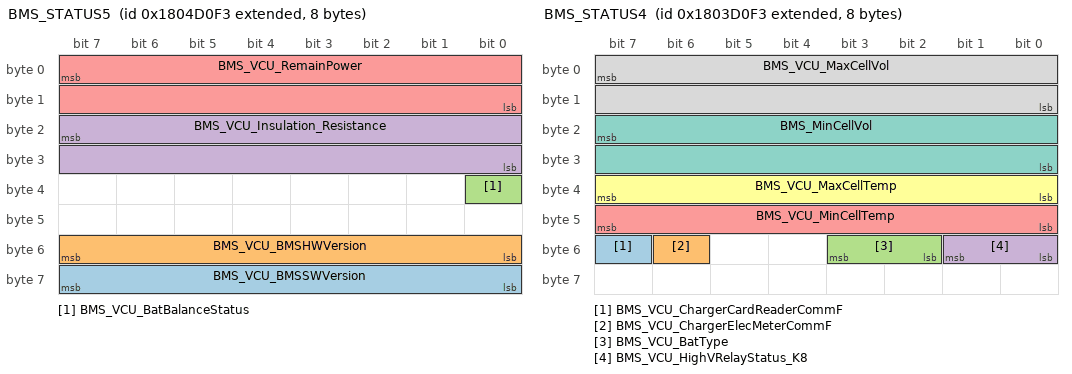
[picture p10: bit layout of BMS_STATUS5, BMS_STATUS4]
BO_ 2550452467 BMS_STATUS5: 8 CAN1
 SG_ BMS_VCU_BMSSWVersion : 63|8@0+ (1,0) [0|0] "" Vector__XXX
 SG_ BMS_VCU_BMSHWVersion : 55|8@0+ (1,0) [0|0] "" Vector__XXX
 SG_ BMS_VCU_BatBalanceStatus : 32|1@0+ (1,0) [0|0] "" Vector__XXX
 SG_ BMS_VCU_Insulation_Resistance : 23|16@0+ (1,0) [0|20000] "kO" Vector__XXX
 SG_ BMS_VCU_RemainPower : 7|16@0+ (0.1,0) [0|10000] "kwh" Vector__XXX

BO_ 2550386931 BMS_STATUS4: 8 CAN1
 SG_ BMS_VCU_ChargerCardReaderCommF : 55|1@0+ (1,0) [0|0] "" Vector__XXX
 SG_ BMS_VCU_ChargerElecMeterCommF : 54|1@0+ (1,0) [0|0] "" Vector__XXX
 SG_ BMS_VCU_BatType : 51|2@0+ (1,0) [0|0] "" Vector__XXX
 SG_ BMS_VCU_HighVRelayStatus_K8 : 49|2@0+ (1,0) [0|0] "" Vector__XXX
 SG_ BMS_VCU_MinCellTemp : 47|8@0+ (1,-40) [-40|210] "C" Vector__XXX
 SG_ BMS_VCU_MaxCellTemp : 39|8@0+ (1,-40) [-40|210] "C" Vector__XXX
 SG_ BMS_MinCellVol : 23|16@0+ (0.01,0) [0|0] "V" Vector__XXX
 SG_ BMS_VCU_MaxCellVol : 7|16@0- (0.01,0) [0|100] "V" Vector__XXX

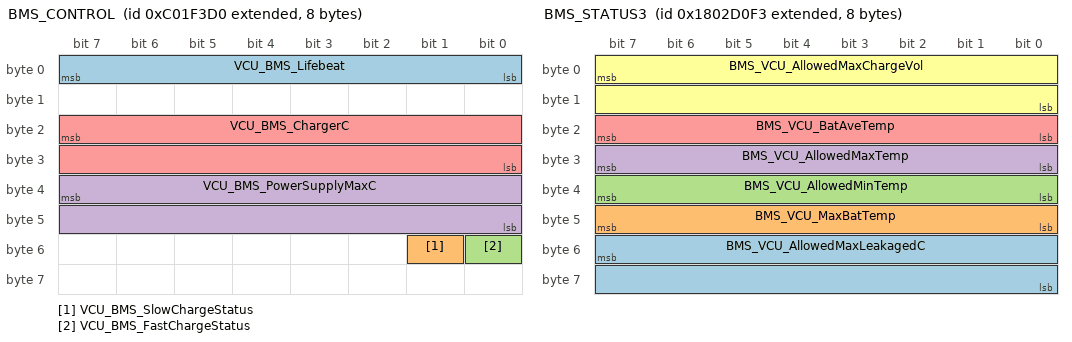
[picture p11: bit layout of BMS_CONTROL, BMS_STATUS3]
BO_ 2348938192 BMS_CONTROL: 8 CAN1
 SG_ VCU_BMS_Lifebeat : 0|8@1+ (1,0) [0|0] "" Vector__XXX
 SG_ VCU_BMS_SlowChargeStatus : 49|1@0+ (1,0) [0|0] "" Vector__XXX
 SG_ VCU_BMS_FastChargeStatus : 48|1@0+ (1,0) [0|0] "" Vector__XXX
 SG_ VCU_BMS_PowerSupplyMaxC : 39|16@0+ (0.1,-5000) [-500|500] "A" Vector__XXX
 SG_ VCU_BMS_ChargerC : 23|16@0+ (0.1,-5000) [-500|500] "A" Vector__XXX

BO_ 2550321395 BMS_STATUS3: 8 CAN1
 SG_ BMS_VCU_AllowedMaxLeakagedC : 55|16@0+ (0.1,-5000) [-500|500] "A" Vector__XXX
 SG_ BMS_VCU_MaxBatTemp : 47|8@0+ (1,-40) [-40|210] "C" Vector__XXX
 SG_ BMS_VCU_AllowedMinTemp : 32|8@1- (1,-40) [-40|210] "C" Vector__XXX
 SG_ BMS_VCU_AllowedMaxTemp : 31|8@0+ (1,-40) [-40|210] "C" Vector__XXX
 SG_ BMS_VCU_BatAveTemp : 23|8@0+ (1,-40) [-40|210] "C" Vector__XXX
 SG_ BMS_VCU_AllowedMaxChargeVol : 7|16@0+ (0.1,0) [0|1000] "V" Vector__XXX

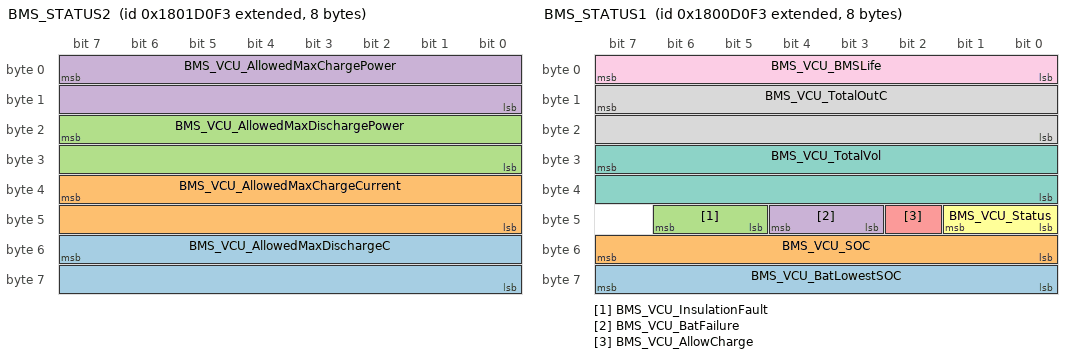
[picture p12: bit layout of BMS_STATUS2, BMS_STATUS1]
BO_ 2550255859 BMS_STATUS2: 8 CAN1
 SG_ BMS_VCU_AllowedMaxDischargeC : 55|16@0+ (0.1,-5000) [-500|500] "A" Vector__XXX
 SG_ BMS_VCU_AllowedMaxChargeCurrent : 39|16@0+ (0.1,-5000) [-500|500] "A" Vector__XXX
 SG_ BMS_VCU_AllowedMaxDischargePower : 23|16@0+ (0.01,-32000) [-320|320] "kw" Vector__XXX
 SG_ BMS_VCU_AllowedMaxChargePower : 7|16@0+ (0.01,-32000) [-320|320] "kw" Vector__XXX

BO_ 2550190323 BMS_STATUS1: 8 CAN1
 SG_ BMS_VCU_BatLowestSOC : 63|8@0+ (0.4,0) [0|0] "%" Vector__XXX
 SG_ BMS_VCU_SOC : 55|8@0+ (0.4,0) [0|100] "%" Vector__XXX
 SG_ BMS_VCU_InsulationFault : 46|2@0+ (1,0) [0|0] "" Vector__XXX
 SG_ BMS_VCU_BatFailure : 44|2@0+ (1,0) [0|0] "" Vector__XXX
 SG_ BMS_VCU_AllowCharge : 42|1@0+ (1,0) [0|0] "" Vector__XXX
 SG_ BMS_VCU_Status : 41|2@0+ (1,0) [0|0] "" Vector__XXX
 SG_ BMS_VCU_TotalVol : 31|16@0+ (0.1,0) [0|1000] "V" Vector__XXX
 SG_ BMS_VCU_TotalOutC : 15|16@0+ (0.1,-5000) [-500|500] "A" Vector__XXX
 SG_ BMS_VCU_BMSLife : 7|8@0+ (1,0) [0|0] "" Vector__XXX

BO_ 2550255784 POWER_STEERING_STATUS2: 2 CAN1
 SG_ POWER_STEERING_SwVersion : 8|8@1- (1,0) [0|0] "" Vector__XXX
 SG_ POWER_STEERING_HwVersion : 0|8@1- (1,0) [0|0] "" Vector__XXX

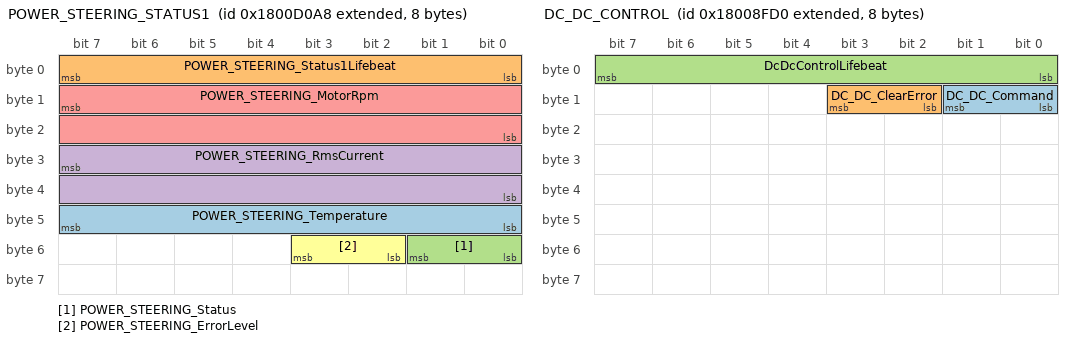
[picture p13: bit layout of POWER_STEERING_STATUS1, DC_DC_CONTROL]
BO_ 2550190248 POWER_STEERING_STATUS1: 8 CAN1
 SG_ POWER_STEERING_Temperature : 40|8@1- (1,-40) [0|0] "C" Vector__XXX
 SG_ POWER_STEERING_Status1Lifebeat : 0|8@1+ (1,0) [0|0] "" Vector__XXX
 SG_ POWER_STEERING_Status : 48|2@1- (1,0) [0|0] "" Vector__XXX
 SG_ POWER_STEERING_RmsCurrent : 31|16@0- (0.1,0) [0|0] "" Vector__XXX
 SG_ POWER_STEERING_MotorRpm : 15|16@0+ (1,0) [0|0] "" Vector__XXX
 SG_ POWER_STEERING_ErrorLevel : 50|2@1- (1,0) [0|0] "" Vector__XXX

BO_ 2550173648 DC_DC_CONTROL: 8 CAN1
 SG_ DC_DC_Command : 8|2@1+ (1,0) [0|0] "" Vector__XXX
 SG_ DC_DC_ClearError : 10|2@1- (1,0) [0|0] "" Vector__XXX
 SG_ DcDcControlLifebeat : 0|8@1+ (1,0) [0|0] "" Vector__XXX

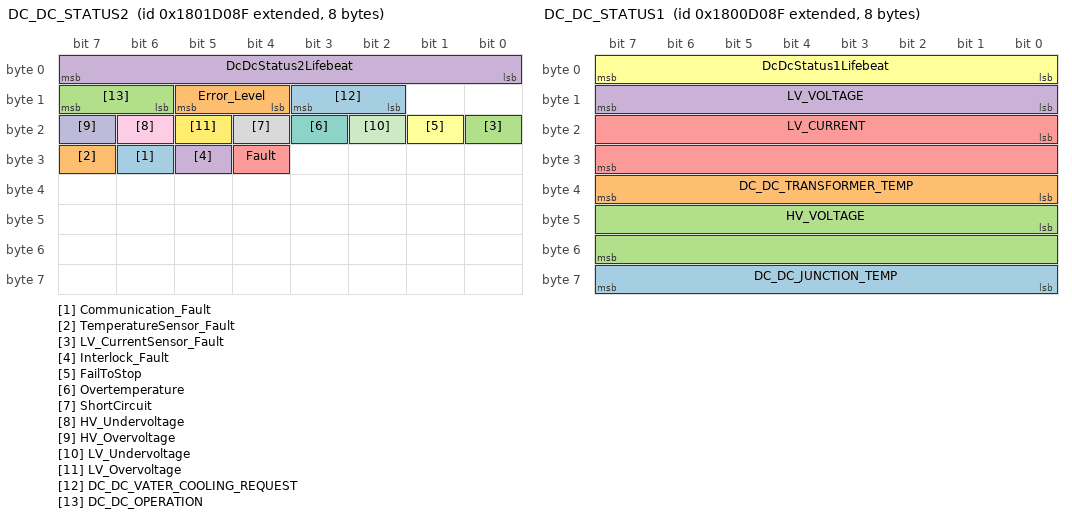
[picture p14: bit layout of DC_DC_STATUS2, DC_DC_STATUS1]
BO_ 2550255759 DC_DC_STATUS2: 8 CAN1
 SG_ Communication_Fault : 30|1@1+ (1,0) [0|0] "" Vector__XXX
 SG_ TemperatureSensor_Fault : 31|1@1+ (1,0) [0|0] "" Vector__XXX
 SG_ LV_CurrentSensor_Fault : 16|1@1+ (1,0) [0|0] "" Vector__XXX
 SG_ Interlock_Fault : 29|1@1+ (1,0) [0|0] "" Vector__XXX
 SG_ Fault : 28|1@1+ (1,0) [0|0] "" Vector__XXX
 SG_ FailToStop : 17|1@1+ (1,0) [0|0] "" Vector__XXX
 SG_ Overtemperature : 19|1@1+ (1,0) [0|0] "" Vector__XXX
 SG_ ShortCircuit : 20|1@1+ (1,0) [0|0] "" Vector__XXX
 SG_ HV_Undervoltage : 22|1@1+ (1,0) [0|0] "" Vector__XXX
 SG_ HV_Overvoltage : 23|1@1+ (1,0) [0|0] "" Vector__XXX
 SG_ LV_Undervoltage : 18|1@1+ (1,0) [0|0] "" Vector__XXX
 SG_ LV_Overvoltage : 21|1@1+ (1,0) [0|0] "" Vector__XXX
 SG_ DC_DC_VATER_COOLING_REQUEST : 10|2@1+ (1,0) [0|0] "" Vector__XXX
 SG_ Error_Level : 12|2@1+ (1,0) [0|0] "" Vector__XXX
 SG_ DC_DC_OPERATION : 14|2@1+ (1,0) [0|0] "" Vector__XXX
 SG_ DcDcStatus2Lifebeat : 0|8@1+ (1,0) [0|0] "" Vector__XXX

BO_ 2550190223 DC_DC_STATUS1: 8 CAN1
 SG_ DC_DC_JUNCTION_TEMP : 56|8@1+ (1,-40) [0|0] "C" Vector__XXX
 SG_ DC_DC_TRANSFORMER_TEMP : 32|8@1+ (1,-40) [0|0] "C" Vector__XXX
 SG_ HV_VOLTAGE : 40|16@1+ (0.1,0) [0|0] "V" Vector__XXX
 SG_ LV_VOLTAGE : 8|8@1+ (0.1,0) [0|0] "V" Vector__XXX
 SG_ LV_CURRENT : 16|16@1+ (0.1,0) [0|0] "A" Vector__XXX
 SG_ DcDcStatus1Lifebeat : 0|8@1+ (1,0) [0|0] "" Vector__XXX

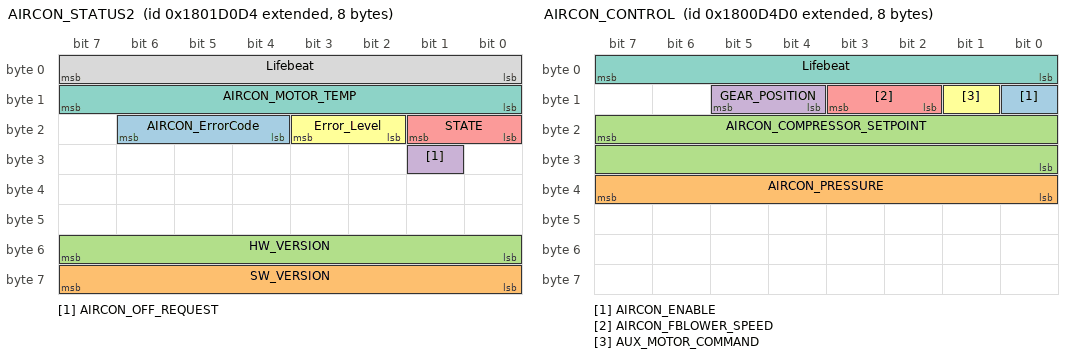
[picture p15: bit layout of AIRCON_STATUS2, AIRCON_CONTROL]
BO_ 2550255828 AIRCON_STATUS2: 8 Vector__XXX
 SG_ AIRCON_ErrorCode : 20|3@1+ (1,0) [0|0] "" Vector__XXX
 SG_ SW_VERSION : 56|8@1- (1,0) [0|0] "" Vector__XXX
 SG_ HW_VERSION : 48|8@1- (1,0) [0|0] "" Vector__XXX
 SG_ AIRCON_OFF_REQUEST : 25|1@1+ (1,0) [0|0] "" Vector__XXX
 SG_ STATE : 16|2@1- (1,0) [0|0] "" Vector__XXX
 SG_ Error_Level : 18|2@1- (1,0) [0|0] "" Vector__XXX
 SG_ AIRCON_MOTOR_TEMP : 8|8@1- (1,-40) [0|0] "C" Vector__XXX
 SG_ Lifebeat : 0|8@1+ (1,0) [0|0] "" Vector__XXX

BO_ 2550190292 AIRCON_STATUS1: 8 Vector__XXX
 SG_ HV_VOLTAGE : 31|16@0- (0.1,0) [0|0] "V" Vector__XXX
 SG_ HV_CURRENT : 47|16@0- (0.1,0) [0|0] "A" Vector__XXX
 SG_ AIRCON_COMPRESSOR_RPM : 15|16@0- (1,0) [0|0] "rpm" Vector__XXX
 SG_ Lifebeat : 0|8@1+ (1,0) [0|0] "" Vector__XXX

BO_ 2550191312 AIRCON_CONTROL: 8 Vector__XXX
 SG_ AIRCON_ENABLE : 8|1@1+ (1,0) [0|0] "" Vector__XXX
 SG_ AIRCON_PRESSURE : 32|8@1+ (1,0) [0|0] "bar" Vector__XXX
 SG_ AIRCON_COMPRESSOR_SETPOINT : 23|16@0+ (1,0) [0|0] "rpm" Vector__XXX
 SG_ GEAR_POSITION : 12|2@1+ (1,0) [0|0] "" Vector__XXX
 SG_ AIRCON_FBLOWER_SPEED : 10|2@1+ (1,0) [0|0] "" Vector__XXX
 SG_ AUX_MOTOR_COMMAND : 9|1@1+ (1,0) [0|0] "" Vector__XXX
 SG_ Lifebeat : 0|8@1+ (1,0) [0|0] "" Vector__XXX

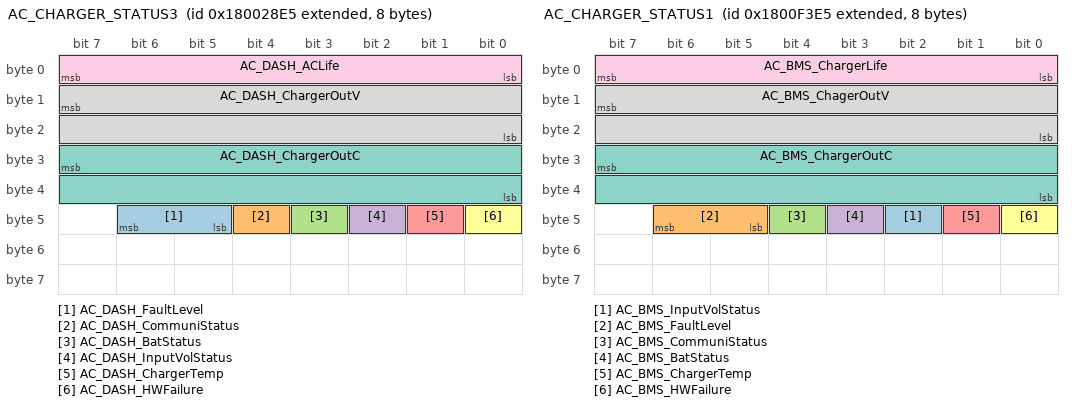
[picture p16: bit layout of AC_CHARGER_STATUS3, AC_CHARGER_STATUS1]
BO_ 2550147301 AC_CHARGER_STATUS3: 8 Vector__XXX
 SG_ AC_DASH_FaultLevel : 46|2@0+ (1,0) [0|0] "" Vector__XXX
 SG_ AC_DASH_CommuniStatus : 44|1@0+ (1,0) [0|0] "" Vector__XXX
 SG_ AC_DASH_BatStatus : 43|1@0+ (1,0) [0|0] "" Vector__XXX
 SG_ AC_DASH_InputVolStatus : 42|1@0+ (1,0) [0|0] "" Vector__XXX
 SG_ AC_DASH_ChargerTemp : 41|1@0+ (1,0) [0|0] "" Vector__XXX
 SG_ AC_DASH_HWFailure : 40|1@0+ (1,0) [0|0] "" Vector__XXX
 SG_ AC_DASH_ChargerOutC : 31|16@0+ (0.1,-5000) [-500|500] "A" Vector__XXX
 SG_ AC_DASH_ChargerOutV : 15|16@0+ (0.1,0) [0|1000] "V" Vector__XXX
 SG_ AC_DASH_ACLife : 7|8@0+ (1,0) [0|0] "" Vector__XXX

BO_ 2550264805 AC_CHARGER_STATUS2: 8 Vector__XXX
 SG_ AC_BMS_ChargerSWVersion : 63|8@0+ (1,0) [0|0] "" Vector__XXX
 SG_ AC_BMS_ChargerHWVersion : 55|8@0+ (1,0) [0|0] "" Vector__XXX
 SG_ AC_BMS_ChargerInC : 23|16@0+ (0.1,-5000) [-500|500] "A" Vector__XXX
 SG_ AC_BMS_ChargerInV : 7|16@0+ (0.1,0) [0|1000] "V" Vector__XXX

BO_ 2550199269 AC_CHARGER_STATUS1: 8 Vector__XXX
 SG_ AC_BMS_InputVolStatus : 42|1@0+ (1,0) [0|0] "" Vector__XXX
 SG_ AC_BMS_FaultLevel : 46|2@0+ (1,0) [0|0] "" Vector__XXX
 SG_ AC_BMS_CommuniStatus : 44|1@0+ (1,0) [0|0] "" Vector__XXX
 SG_ AC_BMS_BatStatus : 43|1@0+ (1,0) [0|0] "" Vector__XXX
 SG_ AC_BMS_ChargerTemp : 41|1@0+ (1,0) [0|0] "" Vector__XXX
 SG_ AC_BMS_HWFailure : 40|1@0+ (1,0) [0|0] "" Vector__XXX
 SG_ AC_BMS_ChargerOutC : 31|16@0+ (0.1,-5000) [-500|500] "A" Vector__XXX
 SG_ AC_BMS_ChagerOutV : 15|16@0+ (0.1,0) [0|1000] "V" Vector__XXX
 SG_ AC_BMS_ChargerLife : 7|8@0+ (1,0) [0|0] "" Vector__XXX

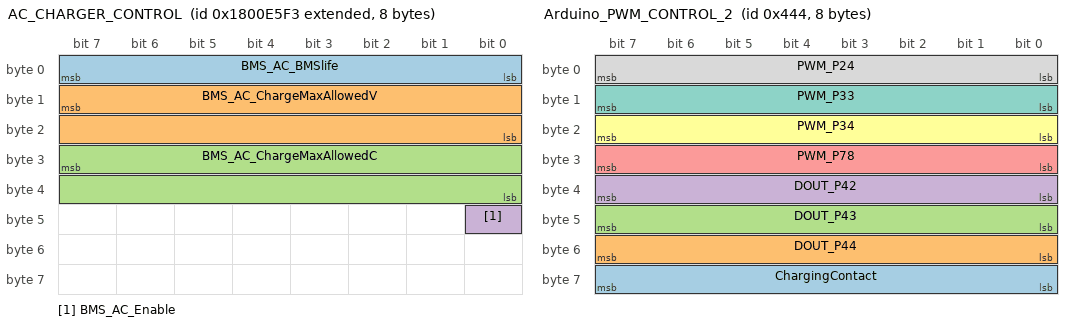
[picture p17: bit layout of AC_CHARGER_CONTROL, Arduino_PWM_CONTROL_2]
BO_ 2550195699 AC_CHARGER_CONTROL: 8 Vector__XXX
 SG_ BMS_AC_BMSlife : 7|8@0+ (1,0) [0|0] "" Vector__XXX
 SG_ BMS_AC_ChargeMaxAllowedV : 15|16@0+ (0.1,0) [0|1000] "V" Vector__XXX
 SG_ BMS_AC_ChargeMaxAllowedC : 31|16@0+ (0.1,-5000) [-500|500] "A" Vector__XXX
 SG_ BMS_AC_Enable : 40|1@0+ (1,0) [0|0] "" Vector__XXX

BO_ 1092 Arduino_PWM_CONTROL_2: 8 CAN1
 SG_ ChargingContact : 56|8@1+ (1,0) [0|1] "" Vector__XXX
 SG_ DOUT_P44 : 48|8@1+ (1,0) [0|1] "" Vector__XXX
 SG_ DOUT_P43 : 40|8@1+ (1,0) [0|1] "" Vector__XXX
 SG_ DOUT_P42 : 32|8@1+ (1,0) [0|1] "" Vector__XXX
 SG_ PWM_P78 : 24|8@1+ (0.39215686274,0) [0|0] "%" Vector__XXX
 SG_ PWM_P34 : 16|8@1+ (0.39215686274,0) [0|0] "%" Vector__XXX
 SG_ PWM_P33 : 8|8@1+ (0.39215686274,0) [0|0] "%" Vector__XXX
 SG_ PWM_P24 : 0|8@1+ (0.39215686274,0) [0|0] "%" Vector__XXX

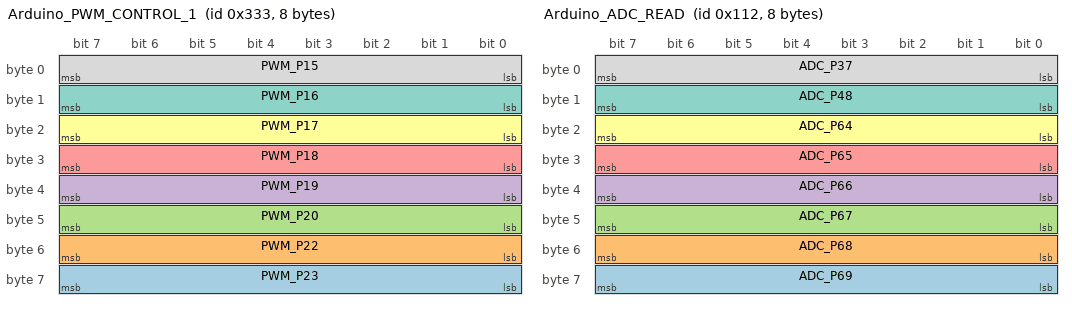
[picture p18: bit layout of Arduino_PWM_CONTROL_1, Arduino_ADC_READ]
BO_ 819 Arduino_PWM_CONTROL_1: 8 CAN1
 SG_ PWM_P23 : 56|8@1+ (0.39215686274,0) [0|0] "%" Vector__XXX
 SG_ PWM_P22 : 48|8@1+ (0.39215686274,0) [0|0] "%" Vector__XXX
 SG_ PWM_P20 : 40|8@1+ (0.39215686274,0) [0|0] "%" Vector__XXX
 SG_ PWM_P19 : 32|8@1+ (0.39215686274,0) [0|0] "%" Vector__XXX
 SG_ PWM_P18 : 24|8@1+ (0.39215686274,0) [0|0] "%" Vector__XXX
 SG_ PWM_P17 : 16|8@1+ (0.39215686274,0) [0|0] "%" Vector__XXX
 SG_ PWM_P16 : 8|8@1+ (0.39215686274,0) [0|0] "%" Vector__XXX
 SG_ PWM_P15 : 0|8@1+ (0.39215686274,0) [0|99.9999999987] "%" Vector__XXX

BO_ 275 Arduino_CHARGING: 1 Vector__XXX
 SG_ ChargingDutyCycle : 0|8@1+ (0.39215686274,0) [0|100] "%" Vector__XXX

BO_ 274 Arduino_ADC_READ: 8 Vector__XXX
 SG_ ADC_P69 : 56|8@1+ (0.01294117647,0) [0|0] "Volts" Vector__XXX
 SG_ ADC_P68 : 48|8@1+ (0.01294117647,0) [0|0] "Volts" Vector__XXX
 SG_ ADC_P67 : 40|8@1+ (0.01294117647,0) [0|0] "Volts" Vector__XXX
 SG_ ADC_P66 : 32|8@1+ (0.01294117647,0) [0|0] "Volts" Vector__XXX
 SG_ ADC_P65 : 24|8@1+ (0.01294117647,0) [0|0] "Volts" Vector__XXX
 SG_ ADC_P64 : 16|8@1+ (0.01294117647,0) [0|0] "Volts" Vector__XXX
 SG_ ADC_P48 : 8|8@1+ (0.01294117647,0) [0|0] "Volts" Vector__XXX
 SG_ ADC_P37 : 0|8@1+ (0.01294117647,0) [0|3.29999999985] "Volts" Vector__XXX

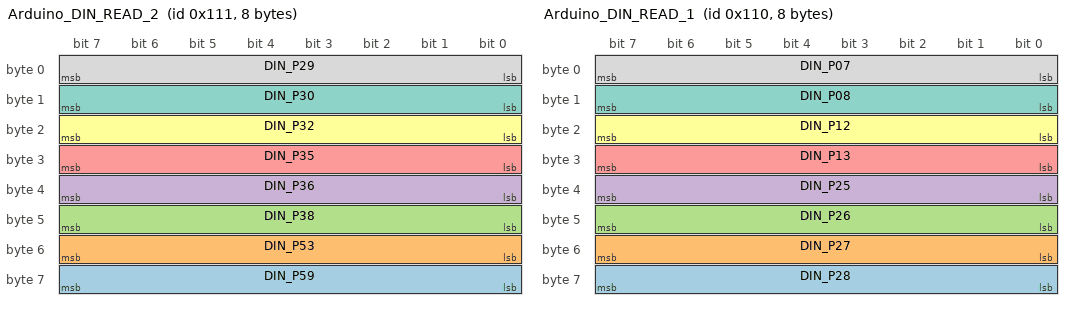
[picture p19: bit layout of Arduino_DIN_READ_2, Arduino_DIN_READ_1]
BO_ 273 Arduino_DIN_READ_2: 8 Vector__XXX
 SG_ DIN_P59 : 56|8@1+ (1,0) [0|255] "" Vector__XXX
 SG_ DIN_P53 : 48|8@1+ (1,0) [0|255] "" Vector__XXX
 SG_ DIN_P38 : 40|8@1+ (1,0) [0|255] "" Vector__XXX
 SG_ DIN_P36 : 32|8@1+ (1,0) [0|255] "" Vector__XXX
 SG_ DIN_P35 : 24|8@1+ (1,0) [0|255] "" Vector__XXX
 SG_ DIN_P32 : 16|8@1+ (1,0) [0|255] "" Vector__XXX
 SG_ DIN_P30 : 8|8@1+ (1,0) [0|255] "" Vector__XXX
 SG_ DIN_P29 : 0|8@1+ (1,0) [0|255] "" Vector__XXX

BO_ 272 Arduino_DIN_READ_1: 8 Vector__XXX
 SG_ DIN_P28 : 56|8@1+ (1,0) [0|255] "" Vector__XXX
 SG_ DIN_P27 : 48|8@1+ (1,0) [0|255] "" Vector__XXX
 SG_ DIN_P26 : 40|8@1+ (1,0) [0|255] "" Vector__XXX
 SG_ DIN_P25 : 32|8@1+ (1,0) [0|255] "" Vector__XXX
 SG_ DIN_P13 : 24|8@1+ (1,0) [0|255] "" Vector__XXX
 SG_ DIN_P12 : 16|8@1+ (1,0) [0|255] "" Vector__XXX
 SG_ DIN_P08 : 8|8@1+ (1,0) [0|255] "" Vector__XXX
 SG_ DIN_P07 : 0|8@1+ (1,0) [0|255] "" Vector__XXX

CM_ BO_ 3221225472 "This is a message for not used signals, created by Vector CANdb++ DBC OLE DB Provider.";
CM_ SG_ 3221225472 VCU_DVD_SOCLowerFailure "0: Normal 1: Fault

(10%-20%) ";
CM_ SG_ 3221225472 VCU_DASH_VehicleController "01: First Level (serious fault)
10: Second level (normal fault)
11: Third level (alarm)
";
CM_ SG_ 3221225472 ERROR_CODE "000:????   Self check fail
001:????  Undervoltage
010:????  Hi Temperature 
011:???? Overvoltage
100:???? Overcurrent
";
CM_ SG_ 2551982323 BMS_DASH_LowestTemp "Valid value 0~250, (-40~210?)
Unit: ?, offset: -40, factor 1?V/bit
";
CM_ SG_ 2551982323 BMS_DASH_HighestTemp "Valid value 0~250, (-40~210?)
Unit: ?, offset: -40, factor 1?V/bit
";
CM_ SG_ 2551982323 BMS_DASH_SingleLowestVol "Valid value 0~1000, (0~10)
Unit: V, offset: 0, factor 0.01 V/bit
";
CM_ SG_ 2551982323 BMS_DASH_SingleHighestVol "Valid value 0~1000, (0~10)
Unit: V, offset: 0, factor 0.01 V/bit
";
CM_ SG_ 2551916787 BMS_DASH_RealCapacity "Valid value 0~255
(0~510 Ah)
Offset:0
Factor 1 Ah/bit
";
CM_ SG_ 2551916787 BMS_DASH_InsulationFault "0: Normal 1:Fault";
CM_ SG_ 2551916787 BMS_DASH_MachineNonRespAlarm "0: Normal 1:Fault";
CM_ SG_ 2551916787 BMS_DASH_SOCLowAlarm "0: Normal 1:Fault";
CM_ SG_ 2551916787 BMS_DASH_VolUnderLimited "0: Normal 1:Fault";
CM_ SG_ 2551916787 BMS_DASH_VolOverLimited "0: Normal 1:Fault ";
CM_ SG_ 2551916787 BMS_DASH_AveVolOverLimited "0: Normal 1:Fault ";
CM_ SG_ 2551916787 BMS_DASH_TotalCOverLimited "0: Normal 1:Fault ";
CM_ SG_ 2551916787 BMS_DASH_TurnOfNegativ "0: Normal 1:Fault";
CM_ SG_ 2551916787 BMS_DASH_TotalVolOverLimited "0: Normal 1:Fault ";
CM_ SG_ 2551916787 BMS_DASH_TempOverLimited "0: Normal 1:Fault ";
CM_ SG_ 2551916787 BMS_DASH_BatteryBalanceFault "0: Normal 1:Fault ";
CM_ SG_ 2550190120 DASH_VCU_BatteryVol "Valid value: 0~ 1000 unit: V,
(0~100), offset: 0, factor 0.1 V/bit
";
CM_ SG_ 2550190120 DASH_VCU_DashSWVersion "Valid value: 0~255, Maintain by dashboard manufactor";
CM_ SG_ 2550190120 DASH_VCU_DashHWVersion "Valid value: 0~255, Maintain by dashboard manufactor ";
CM_ SG_ 2550190120 DASH_VCU_AccumulatedMile "Valid value: 0~16777215unit: km,
(0~16777215), offset: 0, factor 1 km/bit
";
CM_ SG_ 2550540496 VCU_DASH_VCUSWVersionNumber "Valid value: 0~255
It is defined and maintained by VCU factory themselves
";
CM_ SG_ 2550540496 VCU_DASH_VCUHWVersionNumber "Valid value: 0~255
It is defined and maintained by VCU factory themselves
";
CM_ SG_ 2550474960 VCU_DASH_BrakePedalPercentage "Valid value: 0~250 (0~100% ),offset: 0, factor: 0.4 %/bit";
CM_ SG_ 2550474960 VCU_DASH_MotorPhaseV "Valid value: 0~600 (0~600 V),offset: 0, factor: 1 V/bit";
CM_ SG_ 2550474960 VCU_DASH_MotorPhaseC "Valid value: 0~10000 (-500~500 A),offset: -5000, factor: 0.1 A/bit 
The current is negative while charging
";
CM_ SG_ 2550474960 VCU_DASH_MotorDCV "Valid value: 0~10000 (0~1000 V),offset: 0, factor: (0.1 )V/bit";
CM_ SG_ 2550409424 VCU_DASH_MotorHWLoseSignal_P "Motor hardware lose signal protection
(0: Normal 1: protection) 
";
CM_ SG_ 2550409424 VCU_DASH_MotorResolve_P "Motor resolve protection
(0: Normal 1: protection)
";
CM_ SG_ 2550409424 VCU_DASH_MotorLackphase_P "Motor lack-phase protection
(0: Normal 1: protection)
";
CM_ SG_ 2550409424 VCU_DASH_MotorCounterEMF_P "Motor counter EMF protection
(0: Normal 1: protection)
";
CM_ SG_ 2550409424 VCU_DASH_MotorCANFailure_P "Motor CAN communication failure protection
(0: Normal 1: protection) 
";
CM_ SG_ 2550409424 VCU_DASH_MotorOverSpeed_P "Motor overspeed protection
(0: Normal 1: protection)
";
CM_ SG_ 2550409424 VCU_DASH_MotorDriverBoardOverT_P "Motor driver board overtemperature protection
(0: Normal 1: protection) 
";
CM_ SG_ 2550409424 VCU_DASH_MotorBlocking_P "Motor Blocking protection
(0: Normal 1: protection)
";
CM_ SG_ 2550409424 VCU_DASH_MotorOverload_P "Motor overload protecction
(0: Normal 1: protection)
";
CM_ SG_ 2550409424 VCU_DASH_MotorOverTorque_P "Motor overtorque protection 
(0: Normal 1: protection)
";
CM_ SG_ 2550409424 VCU_DASH_MotorBusLineOverV_P "Motor bus line overvoltage protection
(0: Normal 1: protection) 
";
CM_ SG_ 2550409424 VCU_DASH_MotorBusLineUnderV_P "Motor bus line undervoltage protection
(0: Normal 1: protection) 
";
CM_ SG_ 2550409424 VCU_DASH_MotorDQOverC_P "Motor dq current overcurrent protection 
(0: Normal 1: protection)
";
CM_ SG_ 2550409424 VCU_DASH_MotorCVOverV_P "Motor Control voltage overvoltage protection
(0: Normal 1: protection)
";
CM_ SG_ 2550409424 VCU_DASH_MotorCVReverseConn_P "Motor control voltage reverse connection protection
(0: Normal 1: protection)
";
CM_ SG_ 2550409424 VCU_DASH_MotorCVUnderV_P "Motor control voltage undervoltage proteciton
(0: Normal 1: protection) 
";
CM_ SG_ 2550409424 VCU_DASH_MotorPhaseOverC_P "Motor phase current overcurrent protection
(0: Normal 1: protection)
";
CM_ SG_ 2550409424 VCU_DASH_MotorBusLineOverC_P "Motor bus line current overcurrent protection  
(0: Normal 1: protection)
";
CM_ SG_ 2550409424 VCU_DASH_MotorOverT_P "Motor over-temperature protection
(0: Normal 1: protection)
";
CM_ SG_ 2550409424 VCU_DASH_MotorIGBTOverT_P "Motor IGBT over-temperature protection
(0: Normal 1: protection) 
";
CM_ SG_ 2550409424 VCU_DASH_MotorBridgeUpDown_P "Motor bridge up and down protection
(0: Normal 1: protection)
";
CM_ SG_ 2550409424 VCU_DASH_MotorDrivePowerUnderV_P "Motor drive power undervoltage protection (0: Normal 1: protection)";
CM_ SG_ 2550409424 VCU_DASH_MotorIGBT_P "Motor IGBT protection (0: Normal 1: protection)";
CM_ SG_ 2550409424 VCU_DASH_RPM "Valid values 0 to 30000 unit rpm, the range (-15000 ~ 15000) rpm, offset -15 000, the scale factor 1rpm / bit.


When the motor vehicle reversed, rpm is negative
";
CM_ SG_ 2550409424 VCU_DASH_DrivingMile "Valid value: 0~65535  (0~65535)km
offset: 0, factor: (1Km/h)/bit 
";
CM_ SG_ 2550409424 VCU_DASH_VehicleSpeed "Valid value: 0~255 (0~255 Km/h),offset: 0, factor: (1Km/h)/bit";
CM_ SG_ 2550343888 VCU_DASH_VehicleController "01: First Level (serious fault)
10: Second level (normal fault)
11: Third level (alarm
";
CM_ SG_ 2550343888 VCU_DASH_SOC "Valid value: 0~250 (0%~100%),offset: 0, factor: 0.4%/bit";
CM_ SG_ 2550343888 VCU_DASH_VacuumLevel "Valid value: 0~200 (0~2Bar),offset: 0, factor: 0.01Bar/bit.";
CM_ SG_ 2550343888 VCU_DASH_MotorControllerTemp "Valid value: 0~250 (-40~210?),offset -40, factor: 1?/bit";
CM_ SG_ 2550343888 VCU_DASH_BatteryStatus "0: No undervoltage
1: Undervoltage 
";
CM_ SG_ 2550343888 VCU_DASH_VacuumPumpFailure "0: No Fault
1: Fault
";
CM_ SG_ 2550343888 VCU_DASH_FanFailure "00: No Fault
01: Low speed fault
10: High Speed Fault
11: All Fault
";
CM_ SG_ 2550343888 VCU_DASH_PumpFailure "0: No Fault
1: Fault
";
CM_ SG_ 2550343888 VCU_DASH_BetterySysFailure "01: First Level (serious fault)
10: Second level (normal fault)
11: Third level (alarm)
";
CM_ SG_ 2550343888 VCU_DASH_MotorSysFailure "00: No Fault";
CM_ SG_ 2550343888 VCU_DASH_VehicleMode "000: Stop
001: Charging while stop
010: Pure electric driving
011: Regenerative brake
100: Limp Home
";
CM_ SG_ 2550343888 VCU_DASH_ChargeStatus "00: No charge
01: Charger connected
10: Start Charging
11: Stop Charging
";
CM_ SG_ 2550343888 VCU_DASH_BackModulePTC "00: Back Module PTC wind volume 1 gear
01: Back Module PTC wind volume 2 gear
10: Back Module PTC wind volume 3 gear
11: Null
";
CM_ SG_ 2550343888 VCU_DASH_FrontModulePTC "00: Front Module PTC wind volume 1 gear
01: Front Module PTC wind volume 2 gear
10: Front Module PTC wind volume 3 gear
11: Null
";
CM_ SG_ 2550343888 VCU_DASH_GearRange "00: N
01: D
10: R
11: Null";
CM_ SG_ 2550278352 VCU_DASH_PowerOrEcoMode "0: Power mode
1: Economy mode";
CM_ SG_ 2550278352 VCU_DASH_FootBrake "0: No foot brake signal
1: foot brake signal";
CM_ SG_ 2550278352 VCU_DASH_Handbrake "0: Handbrake down
1: Pull Handbrake ";
CM_ SG_ 2550278352 VCU_DASH_AirConditioning "0: Off 
1: On
";
CM_ SG_ 2550278352 VCU_DASH_VacuumPump "0: Off 
1: On
";
CM_ SG_ 2550278352 VCU_DASH_HighSpeedFan "0: OFF
1: ON";
CM_ SG_ 2550278352 VCU_DASH_LowSpeedFan "0: OFF
1: ON";
CM_ SG_ 2550278352 VCU_DASH_Pumps "0: OFF
1: ON";
CM_ SG_ 2550278352 VCU_DASH_AccelPedalPercentage "0xFF: Fault";
CM_ SG_ 2550278352 VCU_DASH_DCStatus "0: No Fault
1: Fault";
CM_ SG_ 2550278352 VCU_DASH_BatteryUndervoltage "0: Battery not undervoltage
1: Battery undervoltage";
CM_ SG_ 2550278352 VCU_DASH_VacuumFailure "0: No Fault
1: Fault";
CM_ SG_ 2550278352 VCU_DASH_ControllerFailure "00: No Fault
01: Stop
10: Fault
11: Alarm";
CM_ SG_ 2550278352 VCU_DASH_VehicleOperatingState "000: Not Ready
001: Ready";
CM_ SG_ 2348863727 MCU_VCU_MotorTorque "Valid value: 0~60000, Unit:N.m
Range: -3000~3000
Offset: -30000
Factor: 0.1 N.m/bit
Negative while regenerating
";
CM_ SG_ 2348863727 MCU_VCU_MCUTemp "Valid value: 0~250, Unit: ?
Range: -40~210
Offset: -40
Factor: 1?/bit
";
CM_ SG_ 2348863727 MCU_VCU_RotationDirection "0: Forward rotation
1: backward rotation
";
CM_ SG_ 2348863727 MCU_VCU_PrechargeStatus "0: not done
1:done
";
CM_ SG_ 2348863727 MCU_VCU_MotorTemp "Valid value: 0~250, Unit: ?
Range: -40~210
Offset: -40
Factor: 1?/bit
";
CM_ SG_ 2348863727 MCU_VCU_MotorRPM "Valid value: 0~30000, Unit:RPM
Range: -15000~15000
Offset: -15000
Factor: 1 rpm/bit
Negative while rotate backward
";
CM_ SG_ 2348863727 MCU_VCU_ModeControl "0: torque
1: limited power mode
";
CM_ SG_ 2348863727 MCU_VCU_MCULowVolSelftest "0: not done
1: done
";
CM_ SG_ 2348863727 MCU_VCU_AllowedCloseK2 "0: not allowed
1: allowed
Recording shows always 1
";
CM_ SG_ 2348863727 MCU_VCU_Idle "0:other 
 1:idle
";
CM_ SG_ 2348863727 MCU_VCU_ErrorStatus "00: no error
01: serious fault, immediately stop
11: general fault, limited speed
11: alarming
";
CM_ SG_ 2348929263 MCU_VCU_MotorMaxBrakeTorq "Valid value: 0~60000, Unit:N.m
Range: -3000~3000
Offset: -30000
Factor: 0.1 N.m/bit
";
CM_ SG_ 2348929263 MCU_VCU_MotorMaxRegenerateP "Valid value: 0~64000, Unit:kw
Range: -320~320
Offset: -32000
Factor: 0.01 kw/bit
";
CM_ SG_ 2348929263 MCU_VCU_MotorMaxDrivenTor "Valid value: 0~60000, Unit:N.m
Range: -3000~3000
Offset: -30000
Factor: 0.1 N.m/bit
";
CM_ SG_ 2348929263 MCU_VCU_MaxDrivePower "Valid value: 0~64000, Unit:kw
Range: -320~320
Offset: -32000
Factor: 0.01 kw/bit
";
CM_ SG_ 2348994799 MCU_VCU_MotorPhaseV "Valid value: 0~600, Unit:V
Range: 0~600
Offset: 0
Factor: 1 V/bit
";
CM_ SG_ 2348994799 MCU_VCU_MotorPhaseC "Valid value: 0~15000, Unit:A
Range: -500~1000
Offset: -5000
Factor: 0.1 A/bit
Negative while charging
";
CM_ SG_ 2348994799 MCU_VCU_MCUType "0x01: supplier";
CM_ SG_ 2348994799 MCU_VCU_MotorDCVol "Valid value: 0~10000, Unit:V
Range: 0~1000
Offset: 0
Factor: 0.1 V/bit
";
CM_ SG_ 2349060335 MCU_VCU_DischargeFailure "0: Normal
1: Failure 
";
CM_ SG_ 2349060335 MCU_VCU_MotorHWLoseSignal_P "0: Normal
1: protection 
";
CM_ SG_ 2349060335 MCU_VCU_MotorResolve_P "0: Normal
1: protection 
";
CM_ SG_ 2349060335 MCU_VCU_MotorLackphase_P "0: Normal
1: protection 
";
CM_ SG_ 2349060335 MCU_VCU_VehicleFaultCircuitRes "0: Normal
1: protection 
";
CM_ SG_ 2349060335 MCU_VCU_MotorCANComuiFailure_P "0: Normal
1: protection 
";
CM_ SG_ 2349060335 MCU_VCU_MotorOverSpeed_P "0: Normal
1: protection 
";
CM_ SG_ 2349060335 MCU_VCU_MotorDriverBoardOverT_P "0: Normal
1: protection 
";
CM_ SG_ 2349060335 MCU_VCU_MotorBlocking_P "0: Normal
1: protection 
";
CM_ SG_ 2349060335 MCU_VCU_MotorOverload_P "0: Normal
1: protection 
";
CM_ SG_ 2349060335 MCU_VCU_MotorOverTorque_P "0: Normal
1: protection 
";
CM_ SG_ 2349060335 MCU_VCU_MotorBusLineOverV_P "0: Normal
1: protection 
";
CM_ SG_ 2349060335 MCU_VCU_MotorBusLineUnderV_P "0: Normal
1: protection 
";
CM_ SG_ 2349060335 MCU_VCU_MotorDQOverC_P "0: Normal
1: protection 
";
CM_ SG_ 2349060335 MCU_VCU_MotorCVOverV_P "0: Normal
1: protection 
";
CM_ SG_ 2349060335 MCU_VCU_MotorCVReverseConn_P "0: Normal
1: protection 
";
CM_ SG_ 2349060335 MCU_VCU_MotorCVUnderV_P "0: Normal
1: protection 
";
CM_ SG_ 2349060335 MCU_VCU_MotorPhaseOverC_P "0: Normal
1: protection 
";
CM_ SG_ 2349060335 MCU_VCU_MotorBusLineOverC_P "0: Normal
1: protection 
";
CM_ SG_ 2349060335 MCU_VCU_MotorOverT_P "0: Normal
1: protection
";
CM_ SG_ 2349060335 MCU_VCU_MotorIGBTOverT_P "0: Normal
1: protection
";
CM_ SG_ 2349060335 MCU_VCU_MotorBridgeUpDown_P "0: Normal
1: protection
";
CM_ SG_ 2349060335 MCU_VCU_MotorDrivePowerUnderV_P "0: Normal
1: protection
";
CM_ SG_ 2349060335 MCU_VCU_MotorIGBT_P "0: Normal
1: protection
";
CM_ SG_ 2349125871 MCU_VCU_MCUSWVersion "Valid value: 0~255";
CM_ SG_ 2349125871 MCU_VCU_MotorPower "Valid value: 0~64000, Unit:kw
Range: 0~640
Offset: 0
Factor: 0.01 kw/bit
";
CM_ SG_ 2349125871 MCU_VCU_MotorDCC "Valid value: 0~10000, Unit:A
Range: 0~1000
Offset: 0
Factor: 0.1 A/bit
";
CM_ SG_ 2349125871 MCU_VCU_MCUHWVersion "Valid value: 0~255";
CM_ SG_ 2348937168 VCU_MCU_VCUSWVersion "Valid value: 0-255";
CM_ SG_ 2348937168 VCU_MCU_VCUHWVersion "Valid value: 0-255";
CM_ SG_ 2348937168 VCU_MCU_BatTotalVol "Valid value: 0~10000, Unit:V
Range: 0~1000
Offset: 0
Factor: 0.1 V/bit
";
CM_ SG_ 2348871632 VCU_MCU_RelayK1Status "0: Open
1: Close
Recording shows transition from 1->0
";
CM_ SG_ 2348871632 VCU_MCU_CapacityDischarge "0: Not Discharge
1: Discharge
Recording shows always =0
";
CM_ SG_ 2348871632 VCU_MCU_K2Status "0: Open
1: Close
Recording shows that after precharge there is transition from 0->1
";
CM_ SG_ 2348871632 VCU_MCU_K2CloseRequest "0: No close request
1: close request
Recording shows always 0
";
CM_ SG_ 2348871632 VCU_MCU_K2CloseRequestVali "0: Open
1: Close
Recording shows always 0
";
CM_ SG_ 2348871632 VCU_MCU_SlopeStopRequest "0: No request
1: request
";
CM_ SG_ 2348871632 VCU_MCU_TorqueSetpoint "Valid value: 0~60000, Unit:N.m
Range: -3000~3000
Offset: -30000
Factor: 0.1 N.m/bit
Negative while regenerating
";
CM_ SG_ 2348871632 VCU_MCU_RPMSetpoint "Valid value: 0~30000, Unit: rpm
Range: -15000~15000
Offset: -15000
Factor: 1 rpm/bit
Always positive no matter forward or backward direction
";
CM_ SG_ 2348871632 VCU_MCU_ModeControl "0: torque
1: limited power mode
";
CM_ SG_ 2348871632 VCU_MCU_Enable "0: turn off
1: turn on
";
CM_ SG_ 2348871632 VCU_MCU_InverterCommand "00: stop
01: forward rotation
10: backward rotation
11: idle
";
CM_ SG_ 2348871632 VCU_MCU_DrivenCommand "00: invalid
01: driven
10: regenerating
";
CM_ SG_ 2348871632 VCU_MCU_CarStatus "0x10: OFF
0x20: ACC
0x30: On
0x50: Charging (AC/ DC)
0x60: Allow to drive
Others are invalid
";
CM_ SG_ 2550278387 BMS_DASH_IsolateFailureLevel "00: No Fault
01: First Level (serious fault)
10: Second level (normal fault)
11: Third level (alarm)
";
CM_ SG_ 2550278387 BMS_DASH_BatteryFailureLevel "00: No Fault
01: First Level (serious fault)
10: Second level (normal fault)
11: Third level (alarm)
";
CM_ SG_ 2550278387 BMS_DASH_SOC "Valid value: 0~250 (0~100% ),offset: 0, factor: 0.4 %/bit";
CM_ SG_ 2550278387 BMS_DASH_BatteryTotalC "Valid value: 0~10000 (-500~500 A),offset: -500, factor: 0.1 A/bit 
The current is negative while charging
";
CM_ SG_ 2550278387 BMS_DASH_BatteryTotalV "Valid value: 0~10000 (0~1000 V),offset: 0, factor: (0.1 )V/bit";
CM_ SG_ 2550183120 VCU_DVD_SOCAlarmFailure " 0: Normal 1: Fault
(20%-30%) ";
CM_ SG_ 2550183120 VCU_DVD_DCDCDropped "0: Normal 1: Fault";
CM_ SG_ 2550183120 VCU_DVD_ACControllerDropped "0: Normal 1: Fault";
CM_ SG_ 2550183120 VCU_DVD_PowerSteeringDropped "0: Normal 1: Fault";
CM_ SG_ 2550183120 VCU_DVD_ChargerDropped "0: Normal 1: Fault";
CM_ SG_ 2550183120 VCU_DVD_SevereLowBatteryV "0: Normal 1: Fault
(less than or equal 10.8V)";
CM_ SG_ 2550183120 VCU_DVD_PumpFailure "0: Normal 1: Fault";
CM_ SG_ 2550183120 VCU_DVD_SOC2Low "(>10%)
 0: Normal 1: Fault";
CM_ SG_ 2550183120 VCU_DVD_SOCLow "0: Normal 1: Fault
(10%-20%) ";
CM_ SG_ 2550183120 VCU_DVD_BatterySysDropped "0: Normal 1: Fault";
CM_ SG_ 2550183120 VCU_DVD_MotorDropped "0: Normal 1: Fault";
CM_ SG_ 2550183120 VCU_DVD_BatteryV2Low "0: Normal 1: Fault
(10.9V~11.9V) ";
CM_ SG_ 2550183120 VCU_DVD_VaccumAlarm "0: Normal 1: Fault";
CM_ SG_ 2550183120 VCU_DVD_MotorControllerOverT "0: Normal 1: Fault";
CM_ SG_ 2550183120 VCU_DVD_PowerBatteryV2Low "0: Normal 1: Fault";
CM_ SG_ 2550183120 VCU_DVD_BrakeOC "0: Normal 1: Fault";
CM_ SG_ 2550183120 VCU_DVD_BrakeShort2Ground "0: Normal 1: Fault";
CM_ SG_ 2550183120 VCU_DVD_BrakeShort2Power "0: Normal 1: Fault";
CM_ SG_ 2550183120 VCU_DVD_BrakePerfAlarm "0: Normal 1: Fault";
CM_ SG_ 2550183120 VCU_DVD_AccelOC "0: Normal 1: Fault";
CM_ SG_ 2550183120 VCU_DVD_AccelShort2Ground "0: Normal 1: Fault";
CM_ SG_ 2550183120 VCU_DVD_AccelShort2Power "0: Normal 1: Fault ";
CM_ SG_ 2550183120 VCU_DVD_AccelPerfAlarm "0: Normal 1: Fault";
CM_ SG_ 2550183120 VCU_DVD_ACAlarmLevel "00: No fault
01: Level 1
10: Level 2
11: Level 3
";
CM_ SG_ 2550183120 VCU_DVD_SteeringPumpAlarmL "00: No fault
01: Level 1
10: Level 2
11: Level 3
";
CM_ SG_ 2550183120 VCU_DVD_ChargerAlarmLevel "00: No fault
01: Level 1
10: Level 2
11: Level 3
";
CM_ SG_ 2550183120 VCU_DVD_DCDCAlarmLevel "00: No fault
01: Level 1
10: Level 2
11: Level 3
";
CM_ SG_ 2550183120 VCU_DVD_CarControllerAlarmLevel "00: No fault
01: a (serious fault, immediately stop)
10: two (common fault, speed limited)
11: three (alarm failure, alarm)
";
CM_ SG_ 2550183120 VCU_DVD_BatterySysAlarmLevel "00: No fault
01: a (serious fault, immediately stop)
10: two (common fault, speed limited)
11: three (alarm failure, alarm)
";
CM_ SG_ 2550183120 VCU_DVD_MotorAlarmLevel "00: No fault
01: a (serious fault, immediately stop)
10: two (common fault, speed limited)
11: three (alarm failure, alarm)
";
CM_ SG_ 2550183120 VCU_DVD_VehicleFaultLevel "00: No fault
01: a (serious fault, immediately stop)
10: two (common fault, speed limited)
11: three (alarm failure, alarm)
";
CM_ SG_ 2550248656 VCU_DVD_DischargeFailure "0: Normal 1: Protection";
CM_ SG_ 2550248656 VCU_DVD_MotorHWLoseSignal_P "0: Normal 1: Protection";
CM_ SG_ 2550248656 VCU_DVD_MotorResolve_P "0: Normal 1: Protection";
CM_ SG_ 2550248656 VCU_DVD_MotorLackphase_P "0: Normal 1: Protection";
CM_ SG_ 2550248656 VCU_DVD_VehicleFaultCircuitRes "0: Normal 1: Protection";
CM_ SG_ 2550248656 VCU_DVD_MotorCANComuiFailure_P "0: Normal 1: Protection";
CM_ SG_ 2550248656 VCU_DVD_MotorOverSpeed_P "0: Normal 1: Protection";
CM_ SG_ 2550248656 VCU_DVD_MotorDriverBoardOverT_P "0: Normal 1: Protection";
CM_ SG_ 2550248656 VCU_DVD_MotorBlocking_P "0: Normal 1: Protection";
CM_ SG_ 2550248656 VCU_DVD_MotorOverload_P "0: Normal 1: Protection";
CM_ SG_ 2550248656 VCU_DVD_MotorOverTorque_P "0: Normal 1: Protection";
CM_ SG_ 2550248656 VCU_DVD_MotorBusLineOverV_P "0: Normal 1: Protection";
CM_ SG_ 2550248656 VCU_DVD_MotorBusLineUnderV_P "0: Normal 1: Protection";
CM_ SG_ 2550248656 VCU_DVD_MotorDQOverC_P "0: Normal 1: Protection";
CM_ SG_ 2550248656 VCU_DVD_MotorCVOverV_P "0: Normal 1: Protection";
CM_ SG_ 2550248656 VCU_DVD_MotorCVReverseConn_P "0: Normal 1: Protection";
CM_ SG_ 2550248656 VCU_DVD_MotorCVUnderV_P "0: Normal 1: Protection";
CM_ SG_ 2550248656 VCU_DVD_MotorPhaseOverC_P "0: Normal 1: Protection 
Protecthion of Phase over current	
";
CM_ SG_ 2550248656 VCU_DVD_MotorBusLineOverC_P "0: Normal 1: Protection
Protection of bus over current
";
CM_ SG_ 2550248656 VCU_DVD_MotorOverT_P "0: Normal 1: Protection";
CM_ SG_ 2550248656 VCU_DVD_MotorIGBTOverT_P "0: Normal 1: Protection	";
CM_ SG_ 2550248656 VCU_DVD_MotorBridgeUpDown_P "0: Normal 1: Protection";
CM_ SG_ 2550248656 VCU_DVD_MotorDrivePowerUnderV_P "0: Normal 1: Protection
Protection of driven battery under voltage
";
CM_ SG_ 2550248656 VCU_DVD_MotorIGBT_P "0: Normal 1: Protection	";
CM_ SG_ 2550314192 VCU_DVD_InsulationFault "0: Normal 1: Fault";
CM_ SG_ 2550314192 VCU_DVD_LowerMachineUnrespAlarm "0: Normal 1: Fault
Lower machine unresponsive alarm
";
CM_ SG_ 2550314192 VCU_DVD_CapacityLowAlarm "0: Normal 1: Fault
Low capacity alarm
";
CM_ SG_ 2550314192 VCU_DVD_SingleMinVolGauge "0: Normal 1: Fault
Single minimum voltage overload
";
CM_ SG_ 2550314192 VCU_DVD_SingleMaxVolGauge "0: Normal 1: Fault
Single highest voltage overload
";
CM_ SG_ 2550314192 VCU_DVD_AveVolGauge "0: Normal 1: Fault
Average voltage over limit
";
CM_ SG_ 2550314192 VCU_DVD_TotalCurrentLimit "0: Normal 1: Fault";
CM_ SG_ 2550314192 VCU_DVD_OffMainNegative "0: Normal 1: Fault
Turn off the main negative
";
CM_ SG_ 2550314192 VCU_DVD_TotalVolGauge "0: Normal 1: Fault
Total voltage over the limit
";
CM_ SG_ 2550314192 VCU_DVD_SingleHighestTempGague "0: Normal 1: Fault
SingleHighest Temperature over limit
";
CM_ SG_ 2550314192 VCU_DVD_CellBalancingFault "0: Normal 1: Fault";
CM_ SG_ 2550379728 VCU_DVD_CommuniStatus "0: Communication normal
1: Timeout or receive communication command instruction exception
";
CM_ SG_ 2550379728 VCU_DVD_StartState "0: battery voltage is normal, you can start
1: the battery voltage is abnormal, not allowed to start (to prevent reverse battery)
";
CM_ SG_ 2550379728 VCU_DVD_InputVol "0: The input voltage is normal
1: Error input voltage, charger stopped working 
";
CM_ SG_ 2550379728 VCU_DVD_ChargerTemp "0: Normal
1: charger over temperature protection
";
CM_ SG_ 2550379728 VCU_DVD_HWFailure "0: Normal
1: Hardware failure
";
CM_ SG_ 2550445264 VCU_DVD_CANCommuniBreakdown "0: Normal 1: Fault";
CM_ SG_ 2550445264 VCU_DVD_AbnormalPosition "0: Normal 1: Fault";
CM_ SG_ 2550445264 VCU_DVD_SupplyVolAbnormal "0: Normal 1: Fault
Power supply voltage is abnormal
";
CM_ SG_ 2550445264 VCU_DVD_SelfTestFailure "0: Normal 1: Fault";
CM_ SG_ 2550445264 VCU_DVD_IPMprot "0: Normal 1: Fault";
CM_ SG_ 2550445264 VUC_DVD_Phase "0: Normal 1: Fault";
CM_ SG_ 2550445264 VCU_DVD_Overload "0: Normal 1: Fault";
CM_ SG_ 2550445264 VCU_DVD_Overheat "0: Normal 1: Fault";
CM_ SG_ 2550445264 VCU_DVD_Overcurrent "0: Normal 1: Fault";
CM_ SG_ 2550445264 VCU_DVD_EEROMFailureReadWrite "0: Normal 1: Fault
EEROM Failure to read and write
";
CM_ SG_ 2550445264 VCU_DVD_BusOverV "0: Normal 1: Fault";
CM_ SG_ 2550445264 VCU_DVD_InputUnderV "0: Normal 1: Fault";
CM_ SG_ 2550510800 VCU_DVD_OverCurrentFault "0: Normal 1: Fault";
CM_ SG_ 2550510800 VCU_DVD_OverVolFault "0: Normal 1: Fault";
CM_ SG_ 2550510800 VCU_DVD_OverheatingFault "0: Normal 1: Fault";
CM_ SG_ 2550510800 VCU_DVD_UnderVolFault "0: Normal 1: Fault";
CM_ SG_ 2550510800 VCU_DVD_FailureTestFails "0: Normal 1: Fault";
CM_ SG_ 2550576336 VCU_DVD_TempSensorAlarm "0: Normal 1: Fault";
CM_ SG_ 2550576336 VCU_DVD_Temp2High "0: Normal 1: Fault";
CM_ SG_ 2550576336 VCU_DVD_LowVolLower "0: Normal 1: Fault";
CM_ SG_ 2550576336 VCU_DVD_LowSideCSensorFault "0: Normal 1: Fault";
CM_ SG_ 2550576336 VCU_DVD_InterlockFault "0: Normal 1: Fault";
CM_ SG_ 2550576336 VCU_DVD_LowVol2Low "0: Normal 1: Fault";
CM_ SG_ 2550576336 VCU_DVD_HighVolLower "0: Normal 1: Fault";
CM_ SG_ 2550576336 VCU_DVD_OutputSC "0: Normal 1: Fault";
CM_ SG_ 2550576336 VCU_DVD_HighVol2High "0: Normal 1: Fault";
CM_ SG_ 2550576336 VCU_DVD_Fail2Run "0: Normal 1: Fault";
CM_ SG_ 2550576336 VCU_DVD_Fail2stop "0: Normal 1: Fault";
CM_ SG_ 2550576336 VCU_DVD_DCDCWorkInstrucLoss "0: Normal 1: Fault";
CM_ SG_ 2550518003 BMS_VCU_ChargedPower "Valid value: 0~10000, Unit: kwh
Range: 0~1000
Offset:0
Factor: 0.1 kwh/bit
";
CM_ SG_ 2550518003 BMS_VCU_ChargeTime "Valid value: 0~600, Unit: Min
Range: 0~600
Offset:0
Factor: 1 min/bit 
";
CM_ SG_ 2550518003 BMS_VCU_ChargerOutC "Valid value: 0~10000, Unit: A
Range: -500~500
Offset:-5000
Factor: 0.1 A/bit 
";
CM_ SG_ 2550518003 BMS_VCU_ChargerOutV "Valid value: 0~10000, Unit: kwh
Range: 0~1000
Offset:0
Factor: 0.1 kwh/bit
";
CM_ SG_ 2550452467 BMS_VCU_BMSSWVersion "Valid value: 0~255";
CM_ SG_ 2550452467 BMS_VCU_BMSHWVersion "Valid value: 0~255";
CM_ SG_ 2550452467 BMS_VCU_BatBalanceStatus "0: inactive 1: active ";
CM_ SG_ 2550452467 BMS_VCU_Insulation_Resistance "Valid value: 0~20000, Unit: kO
Range: 0~20000
Offset:0
Factor: 1kO /bit
";
CM_ SG_ 2550452467 BMS_VCU_RemainPower "Valid value: 0~10000, Unit: kwh
Range: 0~1000
Offset:0
Factor: 0.1 kwh/bit
";
CM_ SG_ 2550386931 BMS_VCU_ChargerCardReaderCommF "0: Normal 1: Fault";
CM_ SG_ 2550386931 BMS_VCU_ChargerElecMeterCommF "0: Normal 1: Fault";
CM_ SG_ 2550386931 BMS_VCU_BatType "00:  lithium iron phosphate
01: three yuan battery ";
CM_ SG_ 2550386931 BMS_VCU_HighVRelayStatus_K8 "00: Disconnect the high voltage relays
01: High-voltage relay closes
10: invalid
11: invalid
";
CM_ SG_ 2550386931 BMS_VCU_MinCellTemp "Valid value: 0~250, Unit: ?
Range: -40~210
";
CM_ SG_ 2550386931 BMS_VCU_MaxCellTemp "Valid value: 0~250, Unit: ?
Range: -40~210
";
CM_ SG_ 2550386931 BMS_MinCellVol "Valid value: 0~10000, Unit: V
Range: 0~100V
Offset:0
Factor: 0.01 V/bit
";
CM_ SG_ 2550386931 BMS_VCU_MaxCellVol "Valid value: 0~10000, Unit: V
Range: 0~100
Offset:0
Factor: 0.01 V/bit
";
CM_ SG_ 2348938192 VCU_BMS_SlowChargeStatus "0: Not connected
1: Enter the slow charge state";
CM_ SG_ 2348938192 VCU_BMS_FastChargeStatus "0: Not Connected
1: Enter the fast charge state";
CM_ SG_ 2348938192 VCU_BMS_PowerSupplyMaxC "Valid values 0 to 10,000 A, range (-500 ~ 500) A,
-5000 Offset, scale factor 0.1A / bit. When electric current charge

Flow is negative. 0xFFFF behalf of an illegal value. Invalid value
";
CM_ SG_ 2348938192 VCU_BMS_ChargerC "Valid values 0 to 10,000 A, range (-500 ~ 500) A, offset -5000, scale factor 0.1A / bit. When the charging current is a negative current. 0xFFFF behalf of an illegal value.";
CM_ SG_ 2550321395 BMS_VCU_AllowedMaxLeakagedC "Valid value: 0~10000, Unit: A
Range: -500~500
Offset: -5000
Factor: 0.1 A/bit
Negative when charging
";
CM_ SG_ 2550321395 BMS_VCU_MaxBatTemp "Valid value: 0~250, Unit: ?
Range: -40~210
Offset: -40
Factor: 1?/bit
";
CM_ SG_ 2550321395 BMS_VCU_AllowedMinTemp "Valid value: 0~250, Unit: ?
Range: -40~210
Offset: -40
Factor: 1?/bit
";
CM_ SG_ 2550321395 BMS_VCU_AllowedMaxTemp "Valid value: 0~250, Unit: ?
Range: -40~210
Offset: -40
Factor: 1?/bit
";
CM_ SG_ 2550321395 BMS_VCU_BatAveTemp "Valid value: 0~250, Unit: ?
Range: -40~210
Offset: -40
Factor: 1?/bit
";
CM_ SG_ 2550321395 BMS_VCU_AllowedMaxChargeVol "Valid value: 0~10000, Unit: V
Range: 0~1000
Offset:0
Factor: 0.1 V/bit
";
CM_ SG_ 2550255859 BMS_VCU_AllowedMaxDischargeC "Valid value: 0~10000, Unit: A
Range: -500~500
Offset: -5000
Factor: 0.1 A/bit
Positive when discharging
";
CM_ SG_ 2550255859 BMS_VCU_AllowedMaxChargeCurrent "Valid value: 0~10000, Unit: A
Range: -500~500
Offset: -5000
Factor: 0.1 A/bit
Negative when charging
";
CM_ SG_ 2550255859 BMS_VCU_AllowedMaxDischargePower "Valid value: 0~64000, Unit: kw
Range: -320~320
Offset: -32000
Factor: 0.01 kw/bit
Positive means discharging
";
CM_ SG_ 2550255859 BMS_VCU_AllowedMaxChargePower "Valid value: 0~64000, Unit: kw
Range: -320~320
Offset: -32000
Factor: 0.01 kw/bit
Negative means charging
";
CM_ SG_ 2550190323 BMS_VCU_BatLowestSOC "Valid: 0~250
Range: 0~ 100%
Offset: 0 
Factor: 0.4%/bit
";
CM_ SG_ 2550190323 BMS_VCU_SOC "Valid: 0~250
Range: 0~ 100%
Offset: 0 
Factor: 0.4%/bit
";
CM_ SG_ 2550190323 BMS_VCU_InsulationFault "00: No fault
01: a fault (major fault, stop immediately)
10: 2 fault (common fault, running speed)
11: 3 Fault (fault alarm, alarm
";
CM_ SG_ 2550190323 BMS_VCU_BatFailure "00: no error
01: first level, serious fault, stop immediately
10: second level, limit speed
11: third level, alarm
";
CM_ SG_ 2550190323 BMS_VCU_AllowCharge "0: No allowed to charge
1: Allowed to charge
";
CM_ SG_ 2550190323 BMS_VCU_Status "00: No charging, No discharge
01: discharge
10: charge
";
CM_ SG_ 2550190323 BMS_VCU_TotalVol "Valid value: 0~10000, Unit: V
Range: 0~1000
Offset: 0
Factor: 0.1 V/bit
";
CM_ SG_ 2550190323 BMS_VCU_TotalOutC "Valid value: 0~10000, Unit: A
Range: -500~500
Offset: -5000
Factor: 0.1 A/bit
Negative when charging
";
CM_ SG_ 2550190248 POWER_STEERING_Status "00: the motor is not overloaded, steering pump motor stop;
01: the motor is not overloaded, steering pump motor Run;
10: the motor is not overloaded, steering pump motor fault
";
CM_ SG_ 2550190248 POWER_STEERING_ErrorLevel "00: No fault
01: a fault (major fault)
10: two fault (general failure)
11: three fault (alarm fault)
";
CM_ BO_ 2550173648 "100ms
";
CM_ SG_ 2550173648 DC_DC_Command "00:??Reserved
01:??Start
10:?? Stop
11:??Reserved
";
CM_ SG_ 2550173648 DC_DC_ClearError "??What is this?
00:??Reserved
01:????Protection Claim
10:??Reserved
11:??Reserved
";
CM_ BO_ 2550255759 "100ms
";
CM_ SG_ 2550255759 FailToStop "??";
CM_ SG_ 2550255759 Overtemperature "0: Normal 
1: Error
";
CM_ SG_ 2550255759 ShortCircuit "0: Normal 
1: Error
";
CM_ SG_ 2550255759 HV_Undervoltage "0: Normal 
1: Error
";
CM_ SG_ 2550255759 HV_Overvoltage "0: Normal 
1: Error
";
CM_ SG_ 2550255759 LV_Undervoltage "0: Normal 
1: Error
";
CM_ SG_ 2550255759 LV_Overvoltage "0: Normal 
1: Error
";
CM_ SG_ 2550255759 DC_DC_VATER_COOLING_REQUEST "00: Turn off the cooling system 01: Open water cooling system";
CM_ SG_ 2550255759 Error_Level "00:??? no error
01:??(????,????) Stop now!
10:??(????,????) error: limit speed 
11:??(????,??)warning 
";
CM_ SG_ 2550255759 DC_DC_OPERATION "0000: Reserved
0001: Self
0010: Standby
0011: Start
0100: Running
0101: normal shutdown
0110: protection shutdown
";
CM_ BO_ 2550190223 "100ms
";
CM_ SG_ 2550255828 AIRCON_ErrorCode "000:????   Self check fail
001:????  Undervoltage
010:????  Hi Temperature 
011:???? Overvoltage
100:???? Overcurrent
";
CM_ SG_ 2550255828 AIRCON_OFF_REQUEST "0:???????  no need to turn off
1:??????  Please turn off
";
CM_ SG_ 2550255828 STATE "000:Ready(????,????,Enable ??) 
010:Enable(??????) 
100:PowerUp(???????,???,?????) 
101:Error(?????????) 
";
CM_ SG_ 2550255828 Error_Level "00:??? no error
01:??(????,????) Stop now!
10:??(????,????) error: limit speed 
11:??(????,??)warning 
";
CM_ SG_ 2550255828 AIRCON_MOTOR_TEMP "offset -40C";
CM_ SG_ 2550190292 AIRCON_COMPRESSOR_RPM "feedback";
CM_ BO_ 2550191312 "100ms
";
CM_ SG_ 2550191312 AIRCON_ENABLE "?? What does that mean?";
CM_ SG_ 2550191312 AIRCON_PRESSURE "default 14bar";
CM_ SG_ 2550191312 AIRCON_COMPRESSOR_SETPOINT "default 3500
";
CM_ SG_ 2550191312 GEAR_POSITION "00:??;Compressor RPM:0 
01:D ?;Compressor RPM:1000-2200
10:R ?; 
11:N ? ;Compressor RPM:1000
";
CM_ SG_ 2550191312 AIRCON_FBLOWER_SPEED "(AI input from speed selection switch) 
00:??;off 
01:??; 
10:??; 
11:??; all
";
CM_ SG_ 2550191312 AUX_MOTOR_COMMAND "0:stop 1:Start";
CM_ BO_ 2550147301 "its duplicate from status 2???

";
CM_ SG_ 2550147301 AC_DASH_FaultLevel "00 no error
01:Stop now!
10: error: limit speed 
11)warning 
";
CM_ SG_ 2550147301 AC_DASH_CommuniStatus "0: Communication normal
1: Timeout or receive abnormal signals
";
CM_ SG_ 2550147301 AC_DASH_BatStatus "0: Normal Battery voltage, start allowed
1: Battery Voltage abnormal, start not allowed";
CM_ SG_ 2550147301 AC_DASH_InputVolStatus "0: The input voltage is normal
1: Input voltage error, charger stopped working
";
CM_ SG_ 2550147301 AC_DASH_ChargerTemp "0: Normal
1: The charger temperature protection
";
CM_ SG_ 2550147301 AC_DASH_HWFailure "0: Normal
1: hardware failure";
CM_ SG_ 2550147301 AC_DASH_ChargerOutC "Valid value: 0~10000, Unit: A
Range: -500~500
Offset: -5000
Factor: 0.1 A/bit
When charging the current is negative
";
CM_ SG_ 2550147301 AC_DASH_ChargerOutV "Valid value: 0~10000, Unit: V
Range: 0~ 1000
Offset: 0
Factor: 0.1 V/bit
";
CM_ BO_ 2550264805 "1000ms ";
CM_ SG_ 2550264805 AC_BMS_ChargerSWVersion "Valid value: 0~ 255";
CM_ SG_ 2550264805 AC_BMS_ChargerHWVersion "Valid value: 0~ 255";
CM_ SG_ 2550264805 AC_BMS_ChargerInC "Valid value: 0~10000, Unit: A
Range: -500~500
Offset: -5000
Factor: 0.1 A/bit
positive current when charging";
CM_ SG_ 2550264805 AC_BMS_ChargerInV "Valid value: 0~10000, Unit: V
Range: 0~1000
Offset: 0
Factor: 0.1 V/bit
";
CM_ BO_ 2550199269 "1000ms ";
CM_ SG_ 2550199269 AC_BMS_InputVolStatus "0: normal (220V)
1: error input voltage, charger stop working  ";
CM_ SG_ 2550199269 AC_BMS_FaultLevel "00: no error
01: Serious Failure, stop immediately
10 limit speed 
11: alarm
";
CM_ SG_ 2550199269 AC_BMS_CommuniStatus "0: Communication normal
1: Timeout or receive abnormal signals
";
CM_ SG_ 2550199269 AC_BMS_BatStatus "0: battery voltage is normal, you can start
1: the battery voltage is abnormal, not allowed to start (to prevent reverse battery)
";
CM_ SG_ 2550199269 AC_BMS_ChargerTemp "0: Normal
1: The charger over temperature protection
";
CM_ SG_ 2550199269 AC_BMS_HWFailure "0: Normal
1: hardware failure";
CM_ SG_ 2550199269 AC_BMS_ChargerOutC "Valid value: 0~10000, Unit: A
Range: -500~500
Offset: -5000
Factor: 0.1 A/bit
When charging the current is negative";
CM_ SG_ 2550199269 AC_BMS_ChagerOutV "Valid value: 0~10000, Unit: V
Range: 0~ 1000
Offset: 0
Factor: 0.1 V/bit
";
CM_ BO_ 2550195699 "1000ms ";
CM_ SG_ 2550195699 BMS_AC_ChargeMaxAllowedV "Valid value: 0~10000, Unit: V
Range: 0~ 1000
Offset: 0
Factor: 0.1 V/bit
";
CM_ SG_ 2550195699 BMS_AC_ChargeMaxAllowedC "Valid value: 0~10000, Unit: A
Range: -500~ 500
Offset: -5000
Factor: 0.1 A/bit
When charging the current is negative";
CM_ SG_ 2550195699 BMS_AC_Enable "0: battery protection, turn off the charger output
1: The charger can start to recharge
";
BA_DEF_  "BusType" STRING ;
BA_DEF_DEF_  "BusType" "CAN";
VAL_ 2550343888 VCU_DASH_GearRange 3 "Gear_Invalid" 2 "Gear_Reverse" 1 "Gear_Drive" 0 "Gear_Neutral" ;
